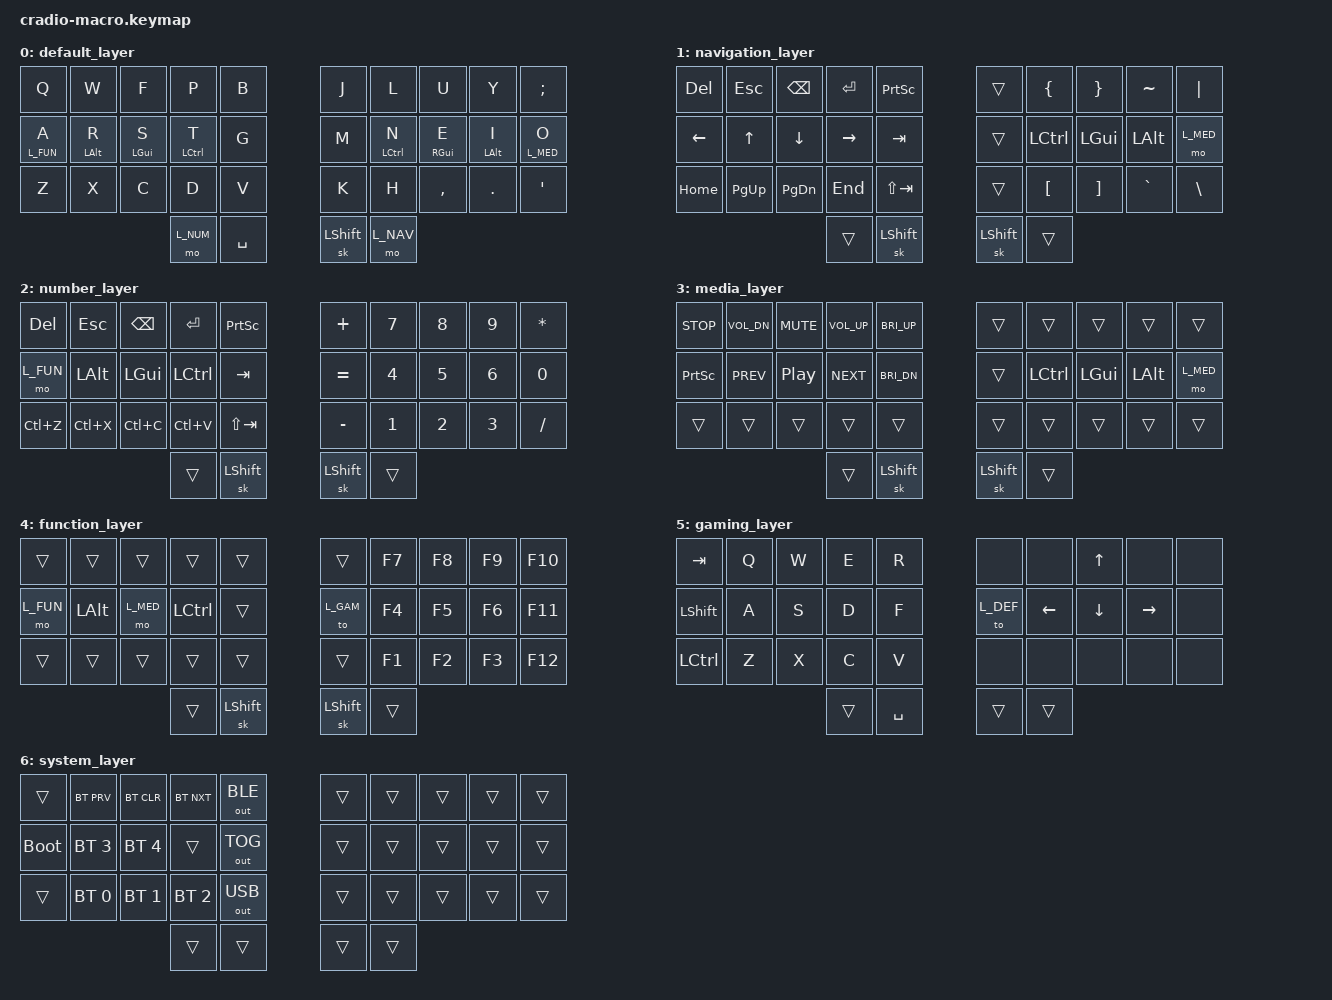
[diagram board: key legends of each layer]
/*
 * Copyright (c) 2020 The ZMK Contributors
 *
 * SPDX-License-Identifier: MIT
 */

#include <behaviors.dtsi>
#include <dt-bindings/zmk/bt.h>
#include <dt-bindings/zmk/keys.h>
#include <dt-bindings/zmk/outputs.h>

// GENERAL KEYS
#define GEN_NONE &none
#define GEN_TRAN &trans

#define GEN_CTRL &kp LCTRL
#define GEN_ALT &kp LALT
#define GEN_GUI &kp LGUI
#define GEN_FN &mo L_FUN
#define GEN_MED &mo L_MED

// DEFAULT LAYER

#define L_DEF 0

#define DEF_Q &kp Q
#define DEF_W &kp W
#define DEF_F &kp F
#define DEF_P &kp P
#define DEF_B &kp B
                        
#define DEF_A &lt L_FUN A 
#define DEF_R &mt LALT R 
#define DEF_S &mt LGUI S
#define DEF_T &mt LCTRL T 
#define DEF_G &kp G
        
#define DEF_Z &kp Z
#define DEF_X &kp X
#define DEF_C &kp C
#define DEF_D &kp D
#define DEF_V &kp V
                        

#define DEF_J &kp J
#define DEF_L &kp L
#define DEF_U &kp U
#define DEF_Y &kp Y
#define DEF_SEMI &kp SEMI

#define DEF_K &kp K
#define DEF_H &kp H
#define DEF_COMA &kp COMMA
#define DEF_DOT &kp DOT
#define DEF_QUOT &kp SQT

#define DEF_M &kp M
#define DEF_N &mt LCTRL N
#define DEF_E &mt RGUI E
#define DEF_I &mt LALT I 
#define DEF_O &lt L_MED O

#define DEF_SPC  &kp SPC
#define DEF_NAV  &mo L_NAV
#define DEF_NUM  &mo L_NUM
#define DEF_SHFT &sk LSHIFT

// NAVIGATION LAYER
#define L_NAV 1

#define NAV_CAPS &kp CAPS
#define NAV_BSLH &kp BSLH
#define NAV_PIPE &kp PIPE
#define NAV_HOME &kp HOME
#define NAV_UP &kp UP
#define NAV_END &kp END
#define NAV_PGUP &kp PG_UP

#define NAV_ESC &kp ESC
#define NAV_LEFT &kp LEFT
#define NAV_DOWN &kp DOWN
#define NAV_RGHT &kp RIGHT
#define NAV_TAB &kp TAB

#define NAV_GRV &kp GRAVE
#define NAV_TILD &kp TILDE
#define NAV_DEL &kp DEL
#define NAV_BSPC &kp BSPC
#define NAV_RET &kp RET
#define NAV_PGDN &kp PG_DN

// NUM LAYER
#define L_NUM 2

#define NUM_LBKT &kp LBKT
#define NUM_LBRC &kp LBRC
#define NUM_N7 &kp N7 
#define NUM_N8 &kp N8
#define NUM_N9 &kp N9
#define NUM_RBKT &kp RBKT 
#define NUM_RBRC &kp RBRC

#define NUM_EQUL &kp EQUAL
#define NUM_PLUS &kp PLUS
#define NUM_AST  &kp ASTERISK 

#define NUM_N4 &kp N4
#define NUM_N5 &kp N5
#define NUM_N6 &kp N6
#define NUM_N0 &kp N0

#define NUM_MIN &kp MINUS
#define NUM_N1 &kp N1
#define NUM_N2 &kp N2
#define NUM_N3 &kp N3
#define NUM_FSLH &kp FSLH

// MEDIA LAYER
#define L_MED 3

#define MED_BRID &kp C_BRI_DN
#define MED_VOLU &kp C_VOL_UP
#define MED_BRIU &kp C_BRI_UP


#define MED_PRNT &kp PSCRN
#define MED_PREV &kp C_PREV
#define MED_PLAY &kp C_PP
#define MED_NEXT &kp C_NEXT

#define MED_MUTE &kp C_MUTE
#define MED_VOLD &kp C_VOL_DN
#define MED_STOP &kp C_STOP

#define MED_UNDO &kp LC(Z)
#define MED_CUT  &kp LC(X)
#define MED_COPY &kp LC(C)
#define NUM_PST  &kp LC(V)
#define NUM_STAB &kp LS(TAB)

//FUNCTION LAYER
#define L_FUN 4

#define FUN_F7 &kp F7
#define FUN_F8 &kp F8
#define FUN_F9 &kp F9
#define FUN_F10 &kp F10

#define FUN_GAME &to L_GAM
#define FUN_F4 &kp F4
#define FUN_F5 &kp F5
#define FUN_F6 &kp F6
#define FUN_F11 &kp F11

#define FUN_BOOT &bootloader
#define FUN_F1 &kp F1
#define FUN_F2 &kp F2
#define FUN_F3 &kp F3
#define FUN_F13 &kp F12

#define FUN_SPC &kp LC(SPC)

// GAMING LAYER
#define L_GAM 5

#define GAM_TAB &kp TAB
#define GAM_Q &kp Q
#define GAM_W &kp W
#define GAM_E &kp E
#define GAM_R &kp R

#define GAM_LSFT &kp LSHIFT
#define GAM_A &kp A
#define GAM_S &kp S
#define GAM_D &kp D
#define GAM_F &kp F

#define GAM_LCTL &kp LCTRL
#define GAM_Z &kp Z
#define GAM_X &kp X
#define GAM_C &kp C
#define GAM_V &kp V


#define GAM_UP &kp UP

#define GAM_DEF &to L_DEF
#define GAM_LEFT &kp LEFT
#define GAM_DOWN &kp DOWN
#define GAM_RGHT &kp RIGHT

#define GAM_ESC &kp ESC
#define GAM_SPC &kp SPACE

// SYSTEM LAYER
#define L_SYS 6

#define SYS_BOOT &bootloader
#define SYS_BTCL &bt BT_CLR
#define SYS_BTNX &bt BT_NXT
#define SYS_BTPR &bt BT_PRV
#define SYS_BLE &out OUT_BLE
#define SYS_USB &out OUT_USB
#define SYS_OTG &out OUT_TOG
#define SYS_BT0 &bt BT_SEL 0
#define SYS_BT1 &bt BT_SEL 1
#define SYS_BT2 &bt BT_SEL 2
#define SYS_BT3 &bt BT_SEL 3
#define SYS_BT4 &bt BT_SEL 4

// POSITIONS
#define P_Q 0
#define P_W 1
#define P_F 2
#define P_P 3
#define P_B 4
#define P_J 5
#define P_L 6
#define P_U 7
#define P_Y 8
#define P_SEMI 9
#define P_A 10
#define P_R 11
#define P_S 12
#define P_T 13
#define P_G 14
#define P_M 15
#define P_N 16
#define P_E 17
#define P_I 18
#define P_O 19
#define P_Z 20
#define P_X 21
#define P_C 22
#define P_D 23
#define P_V 24
#define P_K 25
#define P_H 26
#define P_COMMA 27
#define P_DOT 28
#define P_SQT 29
#define P_COMBO 31 32

#define P_LALT 30
#define P_SPC 31
#define P_SHFT 32
#define P_RALT 33

#define COMBO_TIMEOUT 100
#define MACRO_TAP 10
#define MACRO_WAIT 0

&mt {
  flavor = "tap-preferred";
  tapping_term_ms = <200>;
};

&lt {
  flavor = "tap-preferred";
  tapping_term_ms = <200>;
};
&sl {
    release-after-ms = <1000>;
};
&sk {
    release-after-ms = <1000>;
    quick-release;
};
/ {
  macros {
    ZMK_MACRO(m_dot,
        wait-ms = <MACRO_WAIT>;
        tap-ms = <MACRO_TAP>;
        bindings = <&kp BSPC &kp DOT &kp SPACE>;
    )
    ZMK_MACRO(m_comma,
        wait-ms = <MACRO_WAIT>;
        tap-ms = <MACRO_TAP>;
        bindings = <&kp BSPC &kp COMMA &kp SPACE>;
    )
    ZMK_MACRO(m_ques,
        wait-ms = <MACRO_WAIT>;
        tap-ms = <MACRO_TAP>;
        bindings = <&kp BSPC &kp QUESTION &kp SPACE>;
    )
    // MACROS START
    ZMK_MACRO(spm_a,
        wait-ms = <MACRO_WAIT>;
        tap-ms = <MACRO_TAP>;
        bindings = <&kp A &kp SPACE>;
    )
    ZMK_MACRO(shm_a,
        wait-ms = <MACRO_WAIT>;
        tap-ms = <MACRO_TAP>;
        bindings = <&sk LSHIFT &kp A &kp SPACE>;
    )
    ZMK_MACRO(spm_I,
        wait-ms = <MACRO_WAIT>;
        tap-ms = <MACRO_TAP>;
        bindings = <&sk LSHIFT &kp I &kp SPACE>;
    )
    ZMK_MACRO(shm_I,
        wait-ms = <MACRO_WAIT>;
        tap-ms = <MACRO_TAP>;
        bindings = <&sk LSHIFT &sk LSHIFT &kp I &kp SPACE>;
    )
    ZMK_MACRO(spm_ISQTm,
        wait-ms = <MACRO_WAIT>;
        tap-ms = <MACRO_TAP>;
        bindings = <&sk LSHIFT &kp I &kp SQT &kp M &kp SPACE>;
    )
    ZMK_MACRO(shm_ISQTm,
        wait-ms = <MACRO_WAIT>;
        tap-ms = <MACRO_TAP>;
        bindings = <&sk LSHIFT &sk LSHIFT &kp I &kp SQT &kp M &kp SPACE>;
    )
    ZMK_MACRO(lm_ISQTm,
        wait-ms = <MACRO_WAIT>;
        tap-ms = <MACRO_TAP>;
        bindings = <&sk LSHIFT &kp I &kp SQT &kp V &kp E &kp SPACE>;
    )
    ZMK_MACRO(lsm_ISQTm,
        wait-ms = <MACRO_WAIT>;
        tap-ms = <MACRO_TAP>;
        bindings = <&sk LSHIFT &sk LSHIFT &kp I &kp SQT &kp V &kp E &kp SPACE>;
    )
    ZMK_MACRO(rm_ISQTm,
        wait-ms = <MACRO_WAIT>;
        tap-ms = <MACRO_TAP>;
        bindings = <&sk LSHIFT &kp I &kp SQT &kp L &kp L &kp SPACE>;
    )
    ZMK_MACRO(rsm_ISQTm,
        wait-ms = <MACRO_WAIT>;
        tap-ms = <MACRO_TAP>;
        bindings = <&sk LSHIFT &sk LSHIFT &kp I &kp SQT &kp L &kp L &kp SPACE>;
    )
    ZMK_MACRO(spm_ISQTve,
        wait-ms = <MACRO_WAIT>;
        tap-ms = <MACRO_TAP>;
        bindings = <&sk LSHIFT &kp I &kp SQT &kp V &kp E &kp SPACE>;
    )
    ZMK_MACRO(shm_ISQTve,
        wait-ms = <MACRO_WAIT>;
        tap-ms = <MACRO_TAP>;
        bindings = <&sk LSHIFT &sk LSHIFT &kp I &kp SQT &kp V &kp E &kp SPACE>;
    )
    ZMK_MACRO(spm_ISQTll,
        wait-ms = <MACRO_WAIT>;
        tap-ms = <MACRO_TAP>;
        bindings = <&sk LSHIFT &kp I &kp SQT &kp L &kp L &kp SPACE>;
    )
    ZMK_MACRO(shm_ISQTll,
        wait-ms = <MACRO_WAIT>;
        tap-ms = <MACRO_TAP>;
        bindings = <&sk LSHIFT &sk LSHIFT &kp I &kp SQT &kp L &kp L &kp SPACE>;
    )
    ZMK_MACRO(spm_an,
        wait-ms = <MACRO_WAIT>;
        tap-ms = <MACRO_TAP>;
        bindings = <&kp A &kp N &kp SPACE>;
    )
    ZMK_MACRO(shm_an,
        wait-ms = <MACRO_WAIT>;
        tap-ms = <MACRO_TAP>;
        bindings = <&sk LSHIFT &kp A &kp N &kp SPACE>;
    )
    ZMK_MACRO(spm_am,
        wait-ms = <MACRO_WAIT>;
        tap-ms = <MACRO_TAP>;
        bindings = <&kp A &kp M &kp SPACE>;
    )
    ZMK_MACRO(shm_am,
        wait-ms = <MACRO_WAIT>;
        tap-ms = <MACRO_TAP>;
        bindings = <&sk LSHIFT &kp A &kp M &kp SPACE>;
    )
    ZMK_MACRO(spm_as,
        wait-ms = <MACRO_WAIT>;
        tap-ms = <MACRO_TAP>;
        bindings = <&kp A &kp S &kp SPACE>;
    )
    ZMK_MACRO(shm_as,
        wait-ms = <MACRO_WAIT>;
        tap-ms = <MACRO_TAP>;
        bindings = <&sk LSHIFT &kp A &kp S &kp SPACE>;
    )
    ZMK_MACRO(spm_at,
        wait-ms = <MACRO_WAIT>;
        tap-ms = <MACRO_TAP>;
        bindings = <&kp A &kp T &kp SPACE>;
    )
    ZMK_MACRO(shm_at,
        wait-ms = <MACRO_WAIT>;
        tap-ms = <MACRO_TAP>;
        bindings = <&sk LSHIFT &kp A &kp T &kp SPACE>;
    )
    ZMK_MACRO(spm_be,
        wait-ms = <MACRO_WAIT>;
        tap-ms = <MACRO_TAP>;
        bindings = <&kp B &kp E &kp SPACE>;
    )
    ZMK_MACRO(shm_be,
        wait-ms = <MACRO_WAIT>;
        tap-ms = <MACRO_TAP>;
        bindings = <&sk LSHIFT &kp B &kp E &kp SPACE>;
    )
    ZMK_MACRO(spm_by,
        wait-ms = <MACRO_WAIT>;
        tap-ms = <MACRO_TAP>;
        bindings = <&kp B &kp Y &kp SPACE>;
    )
    ZMK_MACRO(shm_by,
        wait-ms = <MACRO_WAIT>;
        tap-ms = <MACRO_TAP>;
        bindings = <&sk LSHIFT &kp B &kp Y &kp SPACE>;
    )
    ZMK_MACRO(spm_do,
        wait-ms = <MACRO_WAIT>;
        tap-ms = <MACRO_TAP>;
        bindings = <&kp D &kp O &kp SPACE>;
    )
    ZMK_MACRO(shm_do,
        wait-ms = <MACRO_WAIT>;
        tap-ms = <MACRO_TAP>;
        bindings = <&sk LSHIFT &kp D &kp O &kp SPACE>;
    )
    ZMK_MACRO(lm_do,
        wait-ms = <MACRO_WAIT>;
        tap-ms = <MACRO_TAP>;
        bindings = <&kp D &kp I &kp D &kp SPACE>;
    )
    ZMK_MACRO(lsm_do,
        wait-ms = <MACRO_WAIT>;
        tap-ms = <MACRO_TAP>;
        bindings = <&sk LSHIFT &kp D &kp I &kp D &kp SPACE>;
    )
    ZMK_MACRO(rm_do,
        wait-ms = <MACRO_WAIT>;
        tap-ms = <MACRO_TAP>;
        bindings = <&kp D &kp O &kp I &kp N &kp G &kp SPACE>;
    )
    ZMK_MACRO(rsm_do,
        wait-ms = <MACRO_WAIT>;
        tap-ms = <MACRO_TAP>;
        bindings = <&sk LSHIFT &kp D &kp O &kp I &kp N &kp G &kp SPACE>;
    )
    ZMK_MACRO(spm_donSQTt,
        wait-ms = <MACRO_WAIT>;
        tap-ms = <MACRO_TAP>;
        bindings = <&kp D &kp O &kp N &kp SQT &kp T &kp SPACE>;
    )
    ZMK_MACRO(shm_donSQTt,
        wait-ms = <MACRO_WAIT>;
        tap-ms = <MACRO_TAP>;
        bindings = <&sk LSHIFT &kp D &kp O &kp N &kp SQT &kp T &kp SPACE>;
    )
    ZMK_MACRO(lm_donSQTt,
        wait-ms = <MACRO_WAIT>;
        tap-ms = <MACRO_TAP>;
        bindings = <&kp D &kp I &kp D &kp N &kp SQT &kp T &kp SPACE>;
    )
    ZMK_MACRO(lsm_donSQTt,
        wait-ms = <MACRO_WAIT>;
        tap-ms = <MACRO_TAP>;
        bindings = <&sk LSHIFT &kp D &kp I &kp D &kp N &kp SQT &kp T &kp SPACE>;
    )
    ZMK_MACRO(spm_go,
        wait-ms = <MACRO_WAIT>;
        tap-ms = <MACRO_TAP>;
        bindings = <&kp G &kp O &kp SPACE>;
    )
    ZMK_MACRO(shm_go,
        wait-ms = <MACRO_WAIT>;
        tap-ms = <MACRO_TAP>;
        bindings = <&sk LSHIFT &kp G &kp O &kp SPACE>;
    )
    ZMK_MACRO(spm_he,
        wait-ms = <MACRO_WAIT>;
        tap-ms = <MACRO_TAP>;
        bindings = <&kp H &kp E &kp SPACE>;
    )
    ZMK_MACRO(shm_he,
        wait-ms = <MACRO_WAIT>;
        tap-ms = <MACRO_TAP>;
        bindings = <&sk LSHIFT &kp H &kp E &kp SPACE>;
    )
    ZMK_MACRO(lm_he,
        wait-ms = <MACRO_WAIT>;
        tap-ms = <MACRO_TAP>;
        bindings = <&kp H &kp I &kp S &kp SPACE>;
    )
    ZMK_MACRO(lsm_he,
        wait-ms = <MACRO_WAIT>;
        tap-ms = <MACRO_TAP>;
        bindings = <&sk LSHIFT &kp H &kp I &kp S &kp SPACE>;
    )
    ZMK_MACRO(rm_he,
        wait-ms = <MACRO_WAIT>;
        tap-ms = <MACRO_TAP>;
        bindings = <&kp H &kp I &kp M &kp SPACE>;
    )
    ZMK_MACRO(rsm_he,
        wait-ms = <MACRO_WAIT>;
        tap-ms = <MACRO_TAP>;
        bindings = <&sk LSHIFT &kp H &kp I &kp M &kp SPACE>;
    )
    ZMK_MACRO(spm_hi,
        wait-ms = <MACRO_WAIT>;
        tap-ms = <MACRO_TAP>;
        bindings = <&kp H &kp I &kp SPACE>;
    )
    ZMK_MACRO(shm_hi,
        wait-ms = <MACRO_WAIT>;
        tap-ms = <MACRO_TAP>;
        bindings = <&sk LSHIFT &kp H &kp I &kp SPACE>;
    )
    ZMK_MACRO(lm_hi,
        wait-ms = <MACRO_WAIT>;
        tap-ms = <MACRO_TAP>;
        bindings = <&kp H &kp E &kp Y &kp SPACE>;
    )
    ZMK_MACRO(lsm_hi,
        wait-ms = <MACRO_WAIT>;
        tap-ms = <MACRO_TAP>;
        bindings = <&sk LSHIFT &kp H &kp E &kp Y &kp SPACE>;
    )
    ZMK_MACRO(rm_hi,
        wait-ms = <MACRO_WAIT>;
        tap-ms = <MACRO_TAP>;
        bindings = <&kp G &kp SQT &kp D &kp A &kp Y &kp SPACE>;
    )
    ZMK_MACRO(rsm_hi,
        wait-ms = <MACRO_WAIT>;
        tap-ms = <MACRO_TAP>;
        bindings = <&sk LSHIFT &kp G &kp SQT &kp D &kp A &kp Y &kp SPACE>;
    )
    ZMK_MACRO(spm_if,
        wait-ms = <MACRO_WAIT>;
        tap-ms = <MACRO_TAP>;
        bindings = <&kp I &kp F &kp SPACE>;
    )
    ZMK_MACRO(shm_if,
        wait-ms = <MACRO_WAIT>;
        tap-ms = <MACRO_TAP>;
        bindings = <&sk LSHIFT &kp I &kp F &kp SPACE>;
    )
    ZMK_MACRO(spm_in,
        wait-ms = <MACRO_WAIT>;
        tap-ms = <MACRO_TAP>;
        bindings = <&kp I &kp N &kp SPACE>;
    )
    ZMK_MACRO(shm_in,
        wait-ms = <MACRO_WAIT>;
        tap-ms = <MACRO_TAP>;
        bindings = <&sk LSHIFT &kp I &kp N &kp SPACE>;
    )
    ZMK_MACRO(spm_is,
        wait-ms = <MACRO_WAIT>;
        tap-ms = <MACRO_TAP>;
        bindings = <&kp I &kp S &kp SPACE>;
    )
    ZMK_MACRO(shm_is,
        wait-ms = <MACRO_WAIT>;
        tap-ms = <MACRO_TAP>;
        bindings = <&sk LSHIFT &kp I &kp S &kp SPACE>;
    )
    ZMK_MACRO(lm_is,
        wait-ms = <MACRO_WAIT>;
        tap-ms = <MACRO_TAP>;
        bindings = <&kp I &kp S &kp N &kp SQT &kp T &kp SPACE>;
    )
    ZMK_MACRO(lsm_is,
        wait-ms = <MACRO_WAIT>;
        tap-ms = <MACRO_TAP>;
        bindings = <&sk LSHIFT &kp I &kp S &kp N &kp SQT &kp T &kp SPACE>;
    )
    ZMK_MACRO(spm_it,
        wait-ms = <MACRO_WAIT>;
        tap-ms = <MACRO_TAP>;
        bindings = <&kp I &kp T &kp SPACE>;
    )
    ZMK_MACRO(shm_it,
        wait-ms = <MACRO_WAIT>;
        tap-ms = <MACRO_TAP>;
        bindings = <&sk LSHIFT &kp I &kp T &kp SPACE>;
    )
    ZMK_MACRO(lm_it,
        wait-ms = <MACRO_WAIT>;
        tap-ms = <MACRO_TAP>;
        bindings = <&kp I &kp T &kp S &kp SPACE>;
    )
    ZMK_MACRO(lsm_it,
        wait-ms = <MACRO_WAIT>;
        tap-ms = <MACRO_TAP>;
        bindings = <&sk LSHIFT &kp I &kp T &kp S &kp SPACE>;
    )
    ZMK_MACRO(rm_it,
        wait-ms = <MACRO_WAIT>;
        tap-ms = <MACRO_TAP>;
        bindings = <&kp I &kp T &kp SQT &kp S &kp SPACE>;
    )
    ZMK_MACRO(rsm_it,
        wait-ms = <MACRO_WAIT>;
        tap-ms = <MACRO_TAP>;
        bindings = <&sk LSHIFT &kp I &kp T &kp SQT &kp S &kp SPACE>;
    )
    ZMK_MACRO(spm_me,
        wait-ms = <MACRO_WAIT>;
        tap-ms = <MACRO_TAP>;
        bindings = <&kp M &kp E &kp SPACE>;
    )
    ZMK_MACRO(shm_me,
        wait-ms = <MACRO_WAIT>;
        tap-ms = <MACRO_TAP>;
        bindings = <&sk LSHIFT &kp M &kp E &kp SPACE>;
    )
    ZMK_MACRO(lm_me,
        wait-ms = <MACRO_WAIT>;
        tap-ms = <MACRO_TAP>;
        bindings = <&kp M &kp Y &kp SPACE>;
    )
    ZMK_MACRO(lsm_me,
        wait-ms = <MACRO_WAIT>;
        tap-ms = <MACRO_TAP>;
        bindings = <&sk LSHIFT &kp M &kp Y &kp SPACE>;
    )
    ZMK_MACRO(rm_me,
        wait-ms = <MACRO_WAIT>;
        tap-ms = <MACRO_TAP>;
        bindings = <&kp M &kp I &kp N &kp E &kp SPACE>;
    )
    ZMK_MACRO(rsm_me,
        wait-ms = <MACRO_WAIT>;
        tap-ms = <MACRO_TAP>;
        bindings = <&sk LSHIFT &kp M &kp I &kp N &kp E &kp SPACE>;
    )
    ZMK_MACRO(spm_no,
        wait-ms = <MACRO_WAIT>;
        tap-ms = <MACRO_TAP>;
        bindings = <&kp N &kp O &kp SPACE>;
    )
    ZMK_MACRO(shm_no,
        wait-ms = <MACRO_WAIT>;
        tap-ms = <MACRO_TAP>;
        bindings = <&sk LSHIFT &kp N &kp O &kp SPACE>;
    )
    ZMK_MACRO(spm_of,
        wait-ms = <MACRO_WAIT>;
        tap-ms = <MACRO_TAP>;
        bindings = <&kp O &kp F &kp SPACE>;
    )
    ZMK_MACRO(shm_of,
        wait-ms = <MACRO_WAIT>;
        tap-ms = <MACRO_TAP>;
        bindings = <&sk LSHIFT &kp O &kp F &kp SPACE>;
    )
    ZMK_MACRO(spm_on,
        wait-ms = <MACRO_WAIT>;
        tap-ms = <MACRO_TAP>;
        bindings = <&kp O &kp N &kp SPACE>;
    )
    ZMK_MACRO(shm_on,
        wait-ms = <MACRO_WAIT>;
        tap-ms = <MACRO_TAP>;
        bindings = <&sk LSHIFT &kp O &kp N &kp SPACE>;
    )
    ZMK_MACRO(spm_or,
        wait-ms = <MACRO_WAIT>;
        tap-ms = <MACRO_TAP>;
        bindings = <&kp O &kp R &kp SPACE>;
    )
    ZMK_MACRO(shm_or,
        wait-ms = <MACRO_WAIT>;
        tap-ms = <MACRO_TAP>;
        bindings = <&sk LSHIFT &kp O &kp R &kp SPACE>;
    )
    ZMK_MACRO(spm_so,
        wait-ms = <MACRO_WAIT>;
        tap-ms = <MACRO_TAP>;
        bindings = <&kp S &kp O &kp SPACE>;
    )
    ZMK_MACRO(shm_so,
        wait-ms = <MACRO_WAIT>;
        tap-ms = <MACRO_TAP>;
        bindings = <&sk LSHIFT &kp S &kp O &kp SPACE>;
    )
    ZMK_MACRO(spm_to,
        wait-ms = <MACRO_WAIT>;
        tap-ms = <MACRO_TAP>;
        bindings = <&kp T &kp O &kp SPACE>;
    )
    ZMK_MACRO(shm_to,
        wait-ms = <MACRO_WAIT>;
        tap-ms = <MACRO_TAP>;
        bindings = <&sk LSHIFT &kp T &kp O &kp SPACE>;
    )
    ZMK_MACRO(spm_up,
        wait-ms = <MACRO_WAIT>;
        tap-ms = <MACRO_TAP>;
        bindings = <&kp U &kp P &kp SPACE>;
    )
    ZMK_MACRO(shm_up,
        wait-ms = <MACRO_WAIT>;
        tap-ms = <MACRO_TAP>;
        bindings = <&sk LSHIFT &kp U &kp P &kp SPACE>;
    )
    ZMK_MACRO(spm_us,
        wait-ms = <MACRO_WAIT>;
        tap-ms = <MACRO_TAP>;
        bindings = <&kp U &kp S &kp SPACE>;
    )
    ZMK_MACRO(shm_us,
        wait-ms = <MACRO_WAIT>;
        tap-ms = <MACRO_TAP>;
        bindings = <&sk LSHIFT &kp U &kp S &kp SPACE>;
    )
    ZMK_MACRO(spm_we,
        wait-ms = <MACRO_WAIT>;
        tap-ms = <MACRO_TAP>;
        bindings = <&kp W &kp E &kp SPACE>;
    )
    ZMK_MACRO(shm_we,
        wait-ms = <MACRO_WAIT>;
        tap-ms = <MACRO_TAP>;
        bindings = <&sk LSHIFT &kp W &kp E &kp SPACE>;
    )
    ZMK_MACRO(spm_weSQTre,
        wait-ms = <MACRO_WAIT>;
        tap-ms = <MACRO_TAP>;
        bindings = <&kp W &kp E &kp SQT &kp R &kp E &kp SPACE>;
    )
    ZMK_MACRO(shm_weSQTre,
        wait-ms = <MACRO_WAIT>;
        tap-ms = <MACRO_TAP>;
        bindings = <&sk LSHIFT &kp W &kp E &kp SQT &kp R &kp E &kp SPACE>;
    )
    ZMK_MACRO(lm_weSQTre,
        wait-ms = <MACRO_WAIT>;
        tap-ms = <MACRO_TAP>;
        bindings = <&kp W &kp E &kp SQT &kp V &kp E &kp SPACE>;
    )
    ZMK_MACRO(lsm_weSQTre,
        wait-ms = <MACRO_WAIT>;
        tap-ms = <MACRO_TAP>;
        bindings = <&sk LSHIFT &kp W &kp E &kp SQT &kp V &kp E &kp SPACE>;
    )
    ZMK_MACRO(rm_weSQTre,
        wait-ms = <MACRO_WAIT>;
        tap-ms = <MACRO_TAP>;
        bindings = <&kp W &kp E &kp SQT &kp L &kp L &kp SPACE>;
    )
    ZMK_MACRO(rsm_weSQTre,
        wait-ms = <MACRO_WAIT>;
        tap-ms = <MACRO_TAP>;
        bindings = <&sk LSHIFT &kp W &kp E &kp SQT &kp L &kp L &kp SPACE>;
    )
    ZMK_MACRO(spm_weSQTve,
        wait-ms = <MACRO_WAIT>;
        tap-ms = <MACRO_TAP>;
        bindings = <&kp W &kp E &kp SQT &kp V &kp E &kp SPACE>;
    )
    ZMK_MACRO(shm_weSQTve,
        wait-ms = <MACRO_WAIT>;
        tap-ms = <MACRO_TAP>;
        bindings = <&sk LSHIFT &kp W &kp E &kp SQT &kp V &kp E &kp SPACE>;
    )
    ZMK_MACRO(spm_weSQTll,
        wait-ms = <MACRO_WAIT>;
        tap-ms = <MACRO_TAP>;
        bindings = <&kp W &kp E &kp SQT &kp L &kp L &kp SPACE>;
    )
    ZMK_MACRO(shm_weSQTll,
        wait-ms = <MACRO_WAIT>;
        tap-ms = <MACRO_TAP>;
        bindings = <&sk LSHIFT &kp W &kp E &kp SQT &kp L &kp L &kp SPACE>;
    )
    ZMK_MACRO(spm_OK,
        wait-ms = <MACRO_WAIT>;
        tap-ms = <MACRO_TAP>;
        bindings = <&sk LSHIFT &kp O &sk LSHIFT &kp K &kp SPACE>;
    )
    ZMK_MACRO(shm_OK,
        wait-ms = <MACRO_WAIT>;
        tap-ms = <MACRO_TAP>;
        bindings = <&sk LSHIFT &sk LSHIFT &kp O &sk LSHIFT &kp K &kp SPACE>;
    )
    ZMK_MACRO(spm_all,
        wait-ms = <MACRO_WAIT>;
        tap-ms = <MACRO_TAP>;
        bindings = <&kp A &kp L &kp L &kp SPACE>;
    )
    ZMK_MACRO(shm_all,
        wait-ms = <MACRO_WAIT>;
        tap-ms = <MACRO_TAP>;
        bindings = <&sk LSHIFT &kp A &kp L &kp L &kp SPACE>;
    )
    ZMK_MACRO(spm_and,
        wait-ms = <MACRO_WAIT>;
        tap-ms = <MACRO_TAP>;
        bindings = <&kp A &kp N &kp D &kp SPACE>;
    )
    ZMK_MACRO(shm_and,
        wait-ms = <MACRO_WAIT>;
        tap-ms = <MACRO_TAP>;
        bindings = <&sk LSHIFT &kp A &kp N &kp D &kp SPACE>;
    )
    ZMK_MACRO(spm_any,
        wait-ms = <MACRO_WAIT>;
        tap-ms = <MACRO_TAP>;
        bindings = <&kp A &kp N &kp Y &kp SPACE>;
    )
    ZMK_MACRO(shm_any,
        wait-ms = <MACRO_WAIT>;
        tap-ms = <MACRO_TAP>;
        bindings = <&sk LSHIFT &kp A &kp N &kp Y &kp SPACE>;
    )
    ZMK_MACRO(spm_but,
        wait-ms = <MACRO_WAIT>;
        tap-ms = <MACRO_TAP>;
        bindings = <&kp B &kp U &kp T &kp SPACE>;
    )
    ZMK_MACRO(shm_but,
        wait-ms = <MACRO_WAIT>;
        tap-ms = <MACRO_TAP>;
        bindings = <&sk LSHIFT &kp B &kp U &kp T &kp SPACE>;
    )
    ZMK_MACRO(spm_can,
        wait-ms = <MACRO_WAIT>;
        tap-ms = <MACRO_TAP>;
        bindings = <&kp C &kp A &kp N &kp SPACE>;
    )
    ZMK_MACRO(shm_can,
        wait-ms = <MACRO_WAIT>;
        tap-ms = <MACRO_TAP>;
        bindings = <&sk LSHIFT &kp C &kp A &kp N &kp SPACE>;
    )
    ZMK_MACRO(lm_can,
        wait-ms = <MACRO_WAIT>;
        tap-ms = <MACRO_TAP>;
        bindings = <&kp C &kp A &kp N &kp SQT &kp T &kp SPACE>;
    )
    ZMK_MACRO(lsm_can,
        wait-ms = <MACRO_WAIT>;
        tap-ms = <MACRO_TAP>;
        bindings = <&sk LSHIFT &kp C &kp A &kp N &kp SQT &kp T &kp SPACE>;
    )
    ZMK_MACRO(spm_could,
        wait-ms = <MACRO_WAIT>;
        tap-ms = <MACRO_TAP>;
        bindings = <&kp C &kp O &kp U &kp L &kp D &kp SPACE>;
    )
    ZMK_MACRO(shm_could,
        wait-ms = <MACRO_WAIT>;
        tap-ms = <MACRO_TAP>;
        bindings = <&sk LSHIFT &kp C &kp O &kp U &kp L &kp D &kp SPACE>;
    )
    ZMK_MACRO(lm_could,
        wait-ms = <MACRO_WAIT>;
        tap-ms = <MACRO_TAP>;
        bindings = <&kp C &kp O &kp U &kp L &kp D &kp N &kp SQT &kp T &kp SPACE>;
    )
    ZMK_MACRO(lsm_could,
        wait-ms = <MACRO_WAIT>;
        tap-ms = <MACRO_TAP>;
        bindings = <&sk LSHIFT &kp C &kp O &kp U &kp L &kp D &kp N &kp SQT &kp T &kp SPACE>;
    )
    ZMK_MACRO(spm_day,
        wait-ms = <MACRO_WAIT>;
        tap-ms = <MACRO_TAP>;
        bindings = <&kp D &kp A &kp Y &kp SPACE>;
    )
    ZMK_MACRO(shm_day,
        wait-ms = <MACRO_WAIT>;
        tap-ms = <MACRO_TAP>;
        bindings = <&sk LSHIFT &kp D &kp A &kp Y &kp SPACE>;
    )
    ZMK_MACRO(lm_day,
        wait-ms = <MACRO_WAIT>;
        tap-ms = <MACRO_TAP>;
        bindings = <&kp D &kp A &kp Y &kp S &kp SPACE>;
    )
    ZMK_MACRO(lsm_day,
        wait-ms = <MACRO_WAIT>;
        tap-ms = <MACRO_TAP>;
        bindings = <&sk LSHIFT &kp D &kp A &kp Y &kp S &kp SPACE>;
    )
    ZMK_MACRO(spm_for,
        wait-ms = <MACRO_WAIT>;
        tap-ms = <MACRO_TAP>;
        bindings = <&kp F &kp O &kp R &kp SPACE>;
    )
    ZMK_MACRO(shm_for,
        wait-ms = <MACRO_WAIT>;
        tap-ms = <MACRO_TAP>;
        bindings = <&sk LSHIFT &kp F &kp O &kp R &kp SPACE>;
    )
    ZMK_MACRO(spm_get,
        wait-ms = <MACRO_WAIT>;
        tap-ms = <MACRO_TAP>;
        bindings = <&kp G &kp E &kp T &kp SPACE>;
    )
    ZMK_MACRO(shm_get,
        wait-ms = <MACRO_WAIT>;
        tap-ms = <MACRO_TAP>;
        bindings = <&sk LSHIFT &kp G &kp E &kp T &kp SPACE>;
    )
    ZMK_MACRO(lm_get,
        wait-ms = <MACRO_WAIT>;
        tap-ms = <MACRO_TAP>;
        bindings = <&kp G &kp O &kp T &kp SPACE>;
    )
    ZMK_MACRO(lsm_get,
        wait-ms = <MACRO_WAIT>;
        tap-ms = <MACRO_TAP>;
        bindings = <&sk LSHIFT &kp G &kp O &kp T &kp SPACE>;
    )
    ZMK_MACRO(rm_get,
        wait-ms = <MACRO_WAIT>;
        tap-ms = <MACRO_TAP>;
        bindings = <&kp G &kp E &kp T &kp T &kp I &kp N &kp G &kp SPACE>;
    )
    ZMK_MACRO(rsm_get,
        wait-ms = <MACRO_WAIT>;
        tap-ms = <MACRO_TAP>;
        bindings = <&sk LSHIFT &kp G &kp E &kp T &kp T &kp I &kp N &kp G &kp SPACE>;
    )
    ZMK_MACRO(spm_how,
        wait-ms = <MACRO_WAIT>;
        tap-ms = <MACRO_TAP>;
        bindings = <&kp H &kp O &kp W &kp SPACE>;
    )
    ZMK_MACRO(shm_how,
        wait-ms = <MACRO_WAIT>;
        tap-ms = <MACRO_TAP>;
        bindings = <&sk LSHIFT &kp H &kp O &kp W &kp SPACE>;
    )
    ZMK_MACRO(spm_new,
        wait-ms = <MACRO_WAIT>;
        tap-ms = <MACRO_TAP>;
        bindings = <&kp N &kp E &kp W &kp SPACE>;
    )
    ZMK_MACRO(shm_new,
        wait-ms = <MACRO_WAIT>;
        tap-ms = <MACRO_TAP>;
        bindings = <&sk LSHIFT &kp N &kp E &kp W &kp SPACE>;
    )
    ZMK_MACRO(spm_not,
        wait-ms = <MACRO_WAIT>;
        tap-ms = <MACRO_TAP>;
        bindings = <&kp N &kp O &kp T &kp SPACE>;
    )
    ZMK_MACRO(shm_not,
        wait-ms = <MACRO_WAIT>;
        tap-ms = <MACRO_TAP>;
        bindings = <&sk LSHIFT &kp N &kp O &kp T &kp SPACE>;
    )
    ZMK_MACRO(spm_now,
        wait-ms = <MACRO_WAIT>;
        tap-ms = <MACRO_TAP>;
        bindings = <&kp N &kp O &kp W &kp SPACE>;
    )
    ZMK_MACRO(shm_now,
        wait-ms = <MACRO_WAIT>;
        tap-ms = <MACRO_TAP>;
        bindings = <&sk LSHIFT &kp N &kp O &kp W &kp SPACE>;
    )
    ZMK_MACRO(spm_one,
        wait-ms = <MACRO_WAIT>;
        tap-ms = <MACRO_TAP>;
        bindings = <&kp O &kp N &kp E &kp SPACE>;
    )
    ZMK_MACRO(shm_one,
        wait-ms = <MACRO_WAIT>;
        tap-ms = <MACRO_TAP>;
        bindings = <&sk LSHIFT &kp O &kp N &kp E &kp SPACE>;
    )
    ZMK_MACRO(spm_our,
        wait-ms = <MACRO_WAIT>;
        tap-ms = <MACRO_TAP>;
        bindings = <&kp O &kp U &kp R &kp SPACE>;
    )
    ZMK_MACRO(shm_our,
        wait-ms = <MACRO_WAIT>;
        tap-ms = <MACRO_TAP>;
        bindings = <&sk LSHIFT &kp O &kp U &kp R &kp SPACE>;
    )
    ZMK_MACRO(lm_our,
        wait-ms = <MACRO_WAIT>;
        tap-ms = <MACRO_TAP>;
        bindings = <&kp O &kp U &kp R &kp S &kp SPACE>;
    )
    ZMK_MACRO(lsm_our,
        wait-ms = <MACRO_WAIT>;
        tap-ms = <MACRO_TAP>;
        bindings = <&sk LSHIFT &kp O &kp U &kp R &kp S &kp SPACE>;
    )
    ZMK_MACRO(spm_out,
        wait-ms = <MACRO_WAIT>;
        tap-ms = <MACRO_TAP>;
        bindings = <&kp O &kp U &kp T &kp SPACE>;
    )
    ZMK_MACRO(shm_out,
        wait-ms = <MACRO_WAIT>;
        tap-ms = <MACRO_TAP>;
        bindings = <&sk LSHIFT &kp O &kp U &kp T &kp SPACE>;
    )
    ZMK_MACRO(spm_say,
        wait-ms = <MACRO_WAIT>;
        tap-ms = <MACRO_TAP>;
        bindings = <&kp S &kp A &kp Y &kp SPACE>;
    )
    ZMK_MACRO(shm_say,
        wait-ms = <MACRO_WAIT>;
        tap-ms = <MACRO_TAP>;
        bindings = <&sk LSHIFT &kp S &kp A &kp Y &kp SPACE>;
    )
    ZMK_MACRO(lm_say,
        wait-ms = <MACRO_WAIT>;
        tap-ms = <MACRO_TAP>;
        bindings = <&kp S &kp A &kp I &kp D &kp SPACE>;
    )
    ZMK_MACRO(lsm_say,
        wait-ms = <MACRO_WAIT>;
        tap-ms = <MACRO_TAP>;
        bindings = <&sk LSHIFT &kp S &kp A &kp I &kp D &kp SPACE>;
    )
    ZMK_MACRO(rm_say,
        wait-ms = <MACRO_WAIT>;
        tap-ms = <MACRO_TAP>;
        bindings = <&kp S &kp A &kp Y &kp I &kp N &kp G &kp SPACE>;
    )
    ZMK_MACRO(rsm_say,
        wait-ms = <MACRO_WAIT>;
        tap-ms = <MACRO_TAP>;
        bindings = <&sk LSHIFT &kp S &kp A &kp Y &kp I &kp N &kp G &kp SPACE>;
    )
    ZMK_MACRO(spm_see,
        wait-ms = <MACRO_WAIT>;
        tap-ms = <MACRO_TAP>;
        bindings = <&kp S &kp E &kp E &kp SPACE>;
    )
    ZMK_MACRO(shm_see,
        wait-ms = <MACRO_WAIT>;
        tap-ms = <MACRO_TAP>;
        bindings = <&sk LSHIFT &kp S &kp E &kp E &kp SPACE>;
    )
    ZMK_MACRO(lm_see,
        wait-ms = <MACRO_WAIT>;
        tap-ms = <MACRO_TAP>;
        bindings = <&kp S &kp A &kp W &kp SPACE>;
    )
    ZMK_MACRO(lsm_see,
        wait-ms = <MACRO_WAIT>;
        tap-ms = <MACRO_TAP>;
        bindings = <&sk LSHIFT &kp S &kp A &kp W &kp SPACE>;
    )
    ZMK_MACRO(rm_see,
        wait-ms = <MACRO_WAIT>;
        tap-ms = <MACRO_TAP>;
        bindings = <&kp S &kp E &kp E &kp I &kp N &kp G &kp SPACE>;
    )
    ZMK_MACRO(rsm_see,
        wait-ms = <MACRO_WAIT>;
        tap-ms = <MACRO_TAP>;
        bindings = <&sk LSHIFT &kp S &kp E &kp E &kp I &kp N &kp G &kp SPACE>;
    )
    ZMK_MACRO(spm_she,
        wait-ms = <MACRO_WAIT>;
        tap-ms = <MACRO_TAP>;
        bindings = <&kp S &kp H &kp E &kp SPACE>;
    )
    ZMK_MACRO(shm_she,
        wait-ms = <MACRO_WAIT>;
        tap-ms = <MACRO_TAP>;
        bindings = <&sk LSHIFT &kp S &kp H &kp E &kp SPACE>;
    )
    ZMK_MACRO(lm_she,
        wait-ms = <MACRO_WAIT>;
        tap-ms = <MACRO_TAP>;
        bindings = <&kp H &kp E &kp R &kp SPACE>;
    )
    ZMK_MACRO(lsm_she,
        wait-ms = <MACRO_WAIT>;
        tap-ms = <MACRO_TAP>;
        bindings = <&sk LSHIFT &kp H &kp E &kp R &kp SPACE>;
    )
    ZMK_MACRO(rm_she,
        wait-ms = <MACRO_WAIT>;
        tap-ms = <MACRO_TAP>;
        bindings = <&kp H &kp E &kp R &kp S &kp SPACE>;
    )
    ZMK_MACRO(rsm_she,
        wait-ms = <MACRO_WAIT>;
        tap-ms = <MACRO_TAP>;
        bindings = <&sk LSHIFT &kp H &kp E &kp R &kp S &kp SPACE>;
    )
    ZMK_MACRO(spm_the,
        wait-ms = <MACRO_WAIT>;
        tap-ms = <MACRO_TAP>;
        bindings = <&kp T &kp H &kp E &kp SPACE>;
    )
    ZMK_MACRO(shm_the,
        wait-ms = <MACRO_WAIT>;
        tap-ms = <MACRO_TAP>;
        bindings = <&sk LSHIFT &kp T &kp H &kp E &kp SPACE>;
    )
    ZMK_MACRO(spm_two,
        wait-ms = <MACRO_WAIT>;
        tap-ms = <MACRO_TAP>;
        bindings = <&kp T &kp W &kp O &kp SPACE>;
    )
    ZMK_MACRO(shm_two,
        wait-ms = <MACRO_WAIT>;
        tap-ms = <MACRO_TAP>;
        bindings = <&sk LSHIFT &kp T &kp W &kp O &kp SPACE>;
    )
    ZMK_MACRO(spm_use,
        wait-ms = <MACRO_WAIT>;
        tap-ms = <MACRO_TAP>;
        bindings = <&kp U &kp S &kp E &kp SPACE>;
    )
    ZMK_MACRO(shm_use,
        wait-ms = <MACRO_WAIT>;
        tap-ms = <MACRO_TAP>;
        bindings = <&sk LSHIFT &kp U &kp S &kp E &kp SPACE>;
    )
    ZMK_MACRO(lm_use,
        wait-ms = <MACRO_WAIT>;
        tap-ms = <MACRO_TAP>;
        bindings = <&kp U &kp S &kp E &kp D &kp SPACE>;
    )
    ZMK_MACRO(lsm_use,
        wait-ms = <MACRO_WAIT>;
        tap-ms = <MACRO_TAP>;
        bindings = <&sk LSHIFT &kp U &kp S &kp E &kp D &kp SPACE>;
    )
    ZMK_MACRO(rm_use,
        wait-ms = <MACRO_WAIT>;
        tap-ms = <MACRO_TAP>;
        bindings = <&kp U &kp S &kp I &kp N &kp G &kp SPACE>;
    )
    ZMK_MACRO(rsm_use,
        wait-ms = <MACRO_WAIT>;
        tap-ms = <MACRO_TAP>;
        bindings = <&sk LSHIFT &kp U &kp S &kp I &kp N &kp G &kp SPACE>;
    )
    ZMK_MACRO(spm_was,
        wait-ms = <MACRO_WAIT>;
        tap-ms = <MACRO_TAP>;
        bindings = <&kp W &kp A &kp S &kp SPACE>;
    )
    ZMK_MACRO(shm_was,
        wait-ms = <MACRO_WAIT>;
        tap-ms = <MACRO_TAP>;
        bindings = <&sk LSHIFT &kp W &kp A &kp S &kp SPACE>;
    )
    ZMK_MACRO(spm_way,
        wait-ms = <MACRO_WAIT>;
        tap-ms = <MACRO_TAP>;
        bindings = <&kp W &kp A &kp Y &kp SPACE>;
    )
    ZMK_MACRO(shm_way,
        wait-ms = <MACRO_WAIT>;
        tap-ms = <MACRO_TAP>;
        bindings = <&sk LSHIFT &kp W &kp A &kp Y &kp SPACE>;
    )
    ZMK_MACRO(spm_who,
        wait-ms = <MACRO_WAIT>;
        tap-ms = <MACRO_TAP>;
        bindings = <&kp W &kp H &kp O &kp SPACE>;
    )
    ZMK_MACRO(shm_who,
        wait-ms = <MACRO_WAIT>;
        tap-ms = <MACRO_TAP>;
        bindings = <&sk LSHIFT &kp W &kp H &kp O &kp SPACE>;
    )
    ZMK_MACRO(spm_you,
        wait-ms = <MACRO_WAIT>;
        tap-ms = <MACRO_TAP>;
        bindings = <&kp Y &kp O &kp U &kp SPACE>;
    )
    ZMK_MACRO(shm_you,
        wait-ms = <MACRO_WAIT>;
        tap-ms = <MACRO_TAP>;
        bindings = <&sk LSHIFT &kp Y &kp O &kp U &kp SPACE>;
    )
    ZMK_MACRO(lm_you,
        wait-ms = <MACRO_WAIT>;
        tap-ms = <MACRO_TAP>;
        bindings = <&kp Y &kp O &kp U &kp R &kp SPACE>;
    )
    ZMK_MACRO(lsm_you,
        wait-ms = <MACRO_WAIT>;
        tap-ms = <MACRO_TAP>;
        bindings = <&sk LSHIFT &kp Y &kp O &kp U &kp R &kp SPACE>;
    )
    ZMK_MACRO(rm_you,
        wait-ms = <MACRO_WAIT>;
        tap-ms = <MACRO_TAP>;
        bindings = <&kp Y &kp O &kp U &kp R &kp S &kp SPACE>;
    )
    ZMK_MACRO(rsm_you,
        wait-ms = <MACRO_WAIT>;
        tap-ms = <MACRO_TAP>;
        bindings = <&sk LSHIFT &kp Y &kp O &kp U &kp R &kp S &kp SPACE>;
    )
    ZMK_MACRO(spm_youSQTre,
        wait-ms = <MACRO_WAIT>;
        tap-ms = <MACRO_TAP>;
        bindings = <&kp Y &kp O &kp U &kp SQT &kp R &kp E &kp SPACE>;
    )
    ZMK_MACRO(shm_youSQTre,
        wait-ms = <MACRO_WAIT>;
        tap-ms = <MACRO_TAP>;
        bindings = <&sk LSHIFT &kp Y &kp O &kp U &kp SQT &kp R &kp E &kp SPACE>;
    )
    ZMK_MACRO(lm_youSQTre,
        wait-ms = <MACRO_WAIT>;
        tap-ms = <MACRO_TAP>;
        bindings = <&kp Y &kp O &kp U &kp SQT &kp V &kp E &kp SPACE>;
    )
    ZMK_MACRO(lsm_youSQTre,
        wait-ms = <MACRO_WAIT>;
        tap-ms = <MACRO_TAP>;
        bindings = <&sk LSHIFT &kp Y &kp O &kp U &kp SQT &kp V &kp E &kp SPACE>;
    )
    ZMK_MACRO(rm_youSQTre,
        wait-ms = <MACRO_WAIT>;
        tap-ms = <MACRO_TAP>;
        bindings = <&kp Y &kp O &kp U &kp SQT &kp L &kp L &kp SPACE>;
    )
    ZMK_MACRO(rsm_youSQTre,
        wait-ms = <MACRO_WAIT>;
        tap-ms = <MACRO_TAP>;
        bindings = <&sk LSHIFT &kp Y &kp O &kp U &kp SQT &kp L &kp L &kp SPACE>;
    )
    ZMK_MACRO(spm_youSQTve,
        wait-ms = <MACRO_WAIT>;
        tap-ms = <MACRO_TAP>;
        bindings = <&kp Y &kp O &kp U &kp SQT &kp V &kp E &kp SPACE>;
    )
    ZMK_MACRO(shm_youSQTve,
        wait-ms = <MACRO_WAIT>;
        tap-ms = <MACRO_TAP>;
        bindings = <&sk LSHIFT &kp Y &kp O &kp U &kp SQT &kp V &kp E &kp SPACE>;
    )
    ZMK_MACRO(spm_youSQTll,
        wait-ms = <MACRO_WAIT>;
        tap-ms = <MACRO_TAP>;
        bindings = <&kp Y &kp O &kp U &kp SQT &kp L &kp L &kp SPACE>;
    )
    ZMK_MACRO(shm_youSQTll,
        wait-ms = <MACRO_WAIT>;
        tap-ms = <MACRO_TAP>;
        bindings = <&sk LSHIFT &kp Y &kp O &kp U &kp SQT &kp L &kp L &kp SPACE>;
    )
    ZMK_MACRO(spm_also,
        wait-ms = <MACRO_WAIT>;
        tap-ms = <MACRO_TAP>;
        bindings = <&kp A &kp L &kp S &kp O &kp SPACE>;
    )
    ZMK_MACRO(shm_also,
        wait-ms = <MACRO_WAIT>;
        tap-ms = <MACRO_TAP>;
        bindings = <&sk LSHIFT &kp A &kp L &kp S &kp O &kp SPACE>;
    )
    ZMK_MACRO(spm_back,
        wait-ms = <MACRO_WAIT>;
        tap-ms = <MACRO_TAP>;
        bindings = <&kp B &kp A &kp C &kp K &kp SPACE>;
    )
    ZMK_MACRO(shm_back,
        wait-ms = <MACRO_WAIT>;
        tap-ms = <MACRO_TAP>;
        bindings = <&sk LSHIFT &kp B &kp A &kp C &kp K &kp SPACE>;
    )
    ZMK_MACRO(spm_come,
        wait-ms = <MACRO_WAIT>;
        tap-ms = <MACRO_TAP>;
        bindings = <&kp C &kp O &kp M &kp E &kp SPACE>;
    )
    ZMK_MACRO(shm_come,
        wait-ms = <MACRO_WAIT>;
        tap-ms = <MACRO_TAP>;
        bindings = <&sk LSHIFT &kp C &kp O &kp M &kp E &kp SPACE>;
    )
    ZMK_MACRO(lm_come,
        wait-ms = <MACRO_WAIT>;
        tap-ms = <MACRO_TAP>;
        bindings = <&kp C &kp A &kp M &kp E &kp SPACE>;
    )
    ZMK_MACRO(lsm_come,
        wait-ms = <MACRO_WAIT>;
        tap-ms = <MACRO_TAP>;
        bindings = <&sk LSHIFT &kp C &kp A &kp M &kp E &kp SPACE>;
    )
    ZMK_MACRO(rm_come,
        wait-ms = <MACRO_WAIT>;
        tap-ms = <MACRO_TAP>;
        bindings = <&kp C &kp O &kp M &kp I &kp N &kp G &kp SPACE>;
    )
    ZMK_MACRO(rsm_come,
        wait-ms = <MACRO_WAIT>;
        tap-ms = <MACRO_TAP>;
        bindings = <&sk LSHIFT &kp C &kp O &kp M &kp I &kp N &kp G &kp SPACE>;
    )
    ZMK_MACRO(spm_even,
        wait-ms = <MACRO_WAIT>;
        tap-ms = <MACRO_TAP>;
        bindings = <&kp E &kp V &kp E &kp N &kp SPACE>;
    )
    ZMK_MACRO(shm_even,
        wait-ms = <MACRO_WAIT>;
        tap-ms = <MACRO_TAP>;
        bindings = <&sk LSHIFT &kp E &kp V &kp E &kp N &kp SPACE>;
    )
    ZMK_MACRO(spm_from,
        wait-ms = <MACRO_WAIT>;
        tap-ms = <MACRO_TAP>;
        bindings = <&kp F &kp R &kp O &kp M &kp SPACE>;
    )
    ZMK_MACRO(shm_from,
        wait-ms = <MACRO_WAIT>;
        tap-ms = <MACRO_TAP>;
        bindings = <&sk LSHIFT &kp F &kp R &kp O &kp M &kp SPACE>;
    )
    ZMK_MACRO(spm_give,
        wait-ms = <MACRO_WAIT>;
        tap-ms = <MACRO_TAP>;
        bindings = <&kp G &kp I &kp V &kp E &kp SPACE>;
    )
    ZMK_MACRO(shm_give,
        wait-ms = <MACRO_WAIT>;
        tap-ms = <MACRO_TAP>;
        bindings = <&sk LSHIFT &kp G &kp I &kp V &kp E &kp SPACE>;
    )
    ZMK_MACRO(lm_give,
        wait-ms = <MACRO_WAIT>;
        tap-ms = <MACRO_TAP>;
        bindings = <&kp G &kp A &kp V &kp E &kp SPACE>;
    )
    ZMK_MACRO(lsm_give,
        wait-ms = <MACRO_WAIT>;
        tap-ms = <MACRO_TAP>;
        bindings = <&sk LSHIFT &kp G &kp A &kp V &kp E &kp SPACE>;
    )
    ZMK_MACRO(rm_give,
        wait-ms = <MACRO_WAIT>;
        tap-ms = <MACRO_TAP>;
        bindings = <&kp G &kp I &kp V &kp I &kp N &kp G &kp SPACE>;
    )
    ZMK_MACRO(rsm_give,
        wait-ms = <MACRO_WAIT>;
        tap-ms = <MACRO_TAP>;
        bindings = <&sk LSHIFT &kp G &kp I &kp V &kp I &kp N &kp G &kp SPACE>;
    )
    ZMK_MACRO(spm_good,
        wait-ms = <MACRO_WAIT>;
        tap-ms = <MACRO_TAP>;
        bindings = <&kp G &kp O &kp O &kp D &kp SPACE>;
    )
    ZMK_MACRO(shm_good,
        wait-ms = <MACRO_WAIT>;
        tap-ms = <MACRO_TAP>;
        bindings = <&sk LSHIFT &kp G &kp O &kp O &kp D &kp SPACE>;
    )
    ZMK_MACRO(spm_have,
        wait-ms = <MACRO_WAIT>;
        tap-ms = <MACRO_TAP>;
        bindings = <&kp H &kp A &kp V &kp E &kp SPACE>;
    )
    ZMK_MACRO(shm_have,
        wait-ms = <MACRO_WAIT>;
        tap-ms = <MACRO_TAP>;
        bindings = <&sk LSHIFT &kp H &kp A &kp V &kp E &kp SPACE>;
    )
    ZMK_MACRO(lm_have,
        wait-ms = <MACRO_WAIT>;
        tap-ms = <MACRO_TAP>;
        bindings = <&kp H &kp A &kp D &kp SPACE>;
    )
    ZMK_MACRO(lsm_have,
        wait-ms = <MACRO_WAIT>;
        tap-ms = <MACRO_TAP>;
        bindings = <&sk LSHIFT &kp H &kp A &kp D &kp SPACE>;
    )
    ZMK_MACRO(rm_have,
        wait-ms = <MACRO_WAIT>;
        tap-ms = <MACRO_TAP>;
        bindings = <&kp H &kp A &kp V &kp I &kp N &kp G &kp SPACE>;
    )
    ZMK_MACRO(rsm_have,
        wait-ms = <MACRO_WAIT>;
        tap-ms = <MACRO_TAP>;
        bindings = <&sk LSHIFT &kp H &kp A &kp V &kp I &kp N &kp G &kp SPACE>;
    )
    ZMK_MACRO(spm_into,
        wait-ms = <MACRO_WAIT>;
        tap-ms = <MACRO_TAP>;
        bindings = <&kp I &kp N &kp T &kp O &kp SPACE>;
    )
    ZMK_MACRO(shm_into,
        wait-ms = <MACRO_WAIT>;
        tap-ms = <MACRO_TAP>;
        bindings = <&sk LSHIFT &kp I &kp N &kp T &kp O &kp SPACE>;
    )
    ZMK_MACRO(spm_just,
        wait-ms = <MACRO_WAIT>;
        tap-ms = <MACRO_TAP>;
        bindings = <&kp J &kp U &kp S &kp T &kp SPACE>;
    )
    ZMK_MACRO(shm_just,
        wait-ms = <MACRO_WAIT>;
        tap-ms = <MACRO_TAP>;
        bindings = <&sk LSHIFT &kp J &kp U &kp S &kp T &kp SPACE>;
    )
    ZMK_MACRO(spm_know,
        wait-ms = <MACRO_WAIT>;
        tap-ms = <MACRO_TAP>;
        bindings = <&kp K &kp N &kp O &kp W &kp SPACE>;
    )
    ZMK_MACRO(shm_know,
        wait-ms = <MACRO_WAIT>;
        tap-ms = <MACRO_TAP>;
        bindings = <&sk LSHIFT &kp K &kp N &kp O &kp W &kp SPACE>;
    )
    ZMK_MACRO(lm_know,
        wait-ms = <MACRO_WAIT>;
        tap-ms = <MACRO_TAP>;
        bindings = <&kp K &kp N &kp E &kp W &kp SPACE>;
    )
    ZMK_MACRO(lsm_know,
        wait-ms = <MACRO_WAIT>;
        tap-ms = <MACRO_TAP>;
        bindings = <&sk LSHIFT &kp K &kp N &kp E &kp W &kp SPACE>;
    )
    ZMK_MACRO(rm_know,
        wait-ms = <MACRO_WAIT>;
        tap-ms = <MACRO_TAP>;
        bindings = <&kp K &kp N &kp O &kp W &kp S &kp SPACE>;
    )
    ZMK_MACRO(rsm_know,
        wait-ms = <MACRO_WAIT>;
        tap-ms = <MACRO_TAP>;
        bindings = <&sk LSHIFT &kp K &kp N &kp O &kp W &kp S &kp SPACE>;
    )
    ZMK_MACRO(spm_like,
        wait-ms = <MACRO_WAIT>;
        tap-ms = <MACRO_TAP>;
        bindings = <&kp L &kp I &kp K &kp E &kp SPACE>;
    )
    ZMK_MACRO(shm_like,
        wait-ms = <MACRO_WAIT>;
        tap-ms = <MACRO_TAP>;
        bindings = <&sk LSHIFT &kp L &kp I &kp K &kp E &kp SPACE>;
    )
    ZMK_MACRO(lm_like,
        wait-ms = <MACRO_WAIT>;
        tap-ms = <MACRO_TAP>;
        bindings = <&kp L &kp I &kp K &kp E &kp D &kp SPACE>;
    )
    ZMK_MACRO(lsm_like,
        wait-ms = <MACRO_WAIT>;
        tap-ms = <MACRO_TAP>;
        bindings = <&sk LSHIFT &kp L &kp I &kp K &kp E &kp D &kp SPACE>;
    )
    ZMK_MACRO(rm_like,
        wait-ms = <MACRO_WAIT>;
        tap-ms = <MACRO_TAP>;
        bindings = <&kp L &kp I &kp K &kp E &kp S &kp SPACE>;
    )
    ZMK_MACRO(rsm_like,
        wait-ms = <MACRO_WAIT>;
        tap-ms = <MACRO_TAP>;
        bindings = <&sk LSHIFT &kp L &kp I &kp K &kp E &kp S &kp SPACE>;
    )
    ZMK_MACRO(spm_look,
        wait-ms = <MACRO_WAIT>;
        tap-ms = <MACRO_TAP>;
        bindings = <&kp L &kp O &kp O &kp K &kp SPACE>;
    )
    ZMK_MACRO(shm_look,
        wait-ms = <MACRO_WAIT>;
        tap-ms = <MACRO_TAP>;
        bindings = <&sk LSHIFT &kp L &kp O &kp O &kp K &kp SPACE>;
    )
    ZMK_MACRO(lm_look,
        wait-ms = <MACRO_WAIT>;
        tap-ms = <MACRO_TAP>;
        bindings = <&kp L &kp O &kp O &kp K &kp E &kp D &kp SPACE>;
    )
    ZMK_MACRO(lsm_look,
        wait-ms = <MACRO_WAIT>;
        tap-ms = <MACRO_TAP>;
        bindings = <&sk LSHIFT &kp L &kp O &kp O &kp K &kp E &kp D &kp SPACE>;
    )
    ZMK_MACRO(rm_look,
        wait-ms = <MACRO_WAIT>;
        tap-ms = <MACRO_TAP>;
        bindings = <&kp L &kp O &kp O &kp K &kp I &kp N &kp G &kp SPACE>;
    )
    ZMK_MACRO(rsm_look,
        wait-ms = <MACRO_WAIT>;
        tap-ms = <MACRO_TAP>;
        bindings = <&sk LSHIFT &kp L &kp O &kp O &kp K &kp I &kp N &kp G &kp SPACE>;
    )
    ZMK_MACRO(spm_make,
        wait-ms = <MACRO_WAIT>;
        tap-ms = <MACRO_TAP>;
        bindings = <&kp M &kp A &kp K &kp E &kp SPACE>;
    )
    ZMK_MACRO(shm_make,
        wait-ms = <MACRO_WAIT>;
        tap-ms = <MACRO_TAP>;
        bindings = <&sk LSHIFT &kp M &kp A &kp K &kp E &kp SPACE>;
    )
    ZMK_MACRO(lm_make,
        wait-ms = <MACRO_WAIT>;
        tap-ms = <MACRO_TAP>;
        bindings = <&kp M &kp A &kp D &kp E &kp SPACE>;
    )
    ZMK_MACRO(lsm_make,
        wait-ms = <MACRO_WAIT>;
        tap-ms = <MACRO_TAP>;
        bindings = <&sk LSHIFT &kp M &kp A &kp D &kp E &kp SPACE>;
    )
    ZMK_MACRO(rm_make,
        wait-ms = <MACRO_WAIT>;
        tap-ms = <MACRO_TAP>;
        bindings = <&kp M &kp A &kp K &kp I &kp N &kp G &kp SPACE>;
    )
    ZMK_MACRO(rsm_make,
        wait-ms = <MACRO_WAIT>;
        tap-ms = <MACRO_TAP>;
        bindings = <&sk LSHIFT &kp M &kp A &kp K &kp I &kp N &kp G &kp SPACE>;
    )
    ZMK_MACRO(spm_most,
        wait-ms = <MACRO_WAIT>;
        tap-ms = <MACRO_TAP>;
        bindings = <&kp M &kp O &kp S &kp T &kp SPACE>;
    )
    ZMK_MACRO(shm_most,
        wait-ms = <MACRO_WAIT>;
        tap-ms = <MACRO_TAP>;
        bindings = <&sk LSHIFT &kp M &kp O &kp S &kp T &kp SPACE>;
    )
    ZMK_MACRO(spm_only,
        wait-ms = <MACRO_WAIT>;
        tap-ms = <MACRO_TAP>;
        bindings = <&kp O &kp N &kp L &kp Y &kp SPACE>;
    )
    ZMK_MACRO(shm_only,
        wait-ms = <MACRO_WAIT>;
        tap-ms = <MACRO_TAP>;
        bindings = <&sk LSHIFT &kp O &kp N &kp L &kp Y &kp SPACE>;
    )
    ZMK_MACRO(spm_over,
        wait-ms = <MACRO_WAIT>;
        tap-ms = <MACRO_TAP>;
        bindings = <&kp O &kp V &kp E &kp R &kp SPACE>;
    )
    ZMK_MACRO(shm_over,
        wait-ms = <MACRO_WAIT>;
        tap-ms = <MACRO_TAP>;
        bindings = <&sk LSHIFT &kp O &kp V &kp E &kp R &kp SPACE>;
    )
    ZMK_MACRO(spm_some,
        wait-ms = <MACRO_WAIT>;
        tap-ms = <MACRO_TAP>;
        bindings = <&kp S &kp O &kp M &kp E &kp SPACE>;
    )
    ZMK_MACRO(shm_some,
        wait-ms = <MACRO_WAIT>;
        tap-ms = <MACRO_TAP>;
        bindings = <&sk LSHIFT &kp S &kp O &kp M &kp E &kp SPACE>;
    )
    ZMK_MACRO(spm_take,
        wait-ms = <MACRO_WAIT>;
        tap-ms = <MACRO_TAP>;
        bindings = <&kp T &kp A &kp K &kp E &kp SPACE>;
    )
    ZMK_MACRO(shm_take,
        wait-ms = <MACRO_WAIT>;
        tap-ms = <MACRO_TAP>;
        bindings = <&sk LSHIFT &kp T &kp A &kp K &kp E &kp SPACE>;
    )
    ZMK_MACRO(lm_take,
        wait-ms = <MACRO_WAIT>;
        tap-ms = <MACRO_TAP>;
        bindings = <&kp T &kp O &kp O &kp K &kp SPACE>;
    )
    ZMK_MACRO(lsm_take,
        wait-ms = <MACRO_WAIT>;
        tap-ms = <MACRO_TAP>;
        bindings = <&sk LSHIFT &kp T &kp O &kp O &kp K &kp SPACE>;
    )
    ZMK_MACRO(rm_take,
        wait-ms = <MACRO_WAIT>;
        tap-ms = <MACRO_TAP>;
        bindings = <&kp T &kp A &kp K &kp I &kp N &kp G &kp SPACE>;
    )
    ZMK_MACRO(rsm_take,
        wait-ms = <MACRO_WAIT>;
        tap-ms = <MACRO_TAP>;
        bindings = <&sk LSHIFT &kp T &kp A &kp K &kp I &kp N &kp G &kp SPACE>;
    )
    ZMK_MACRO(spm_than,
        wait-ms = <MACRO_WAIT>;
        tap-ms = <MACRO_TAP>;
        bindings = <&kp T &kp H &kp A &kp N &kp SPACE>;
    )
    ZMK_MACRO(shm_than,
        wait-ms = <MACRO_WAIT>;
        tap-ms = <MACRO_TAP>;
        bindings = <&sk LSHIFT &kp T &kp H &kp A &kp N &kp SPACE>;
    )
    ZMK_MACRO(spm_that,
        wait-ms = <MACRO_WAIT>;
        tap-ms = <MACRO_TAP>;
        bindings = <&kp T &kp H &kp A &kp T &kp SPACE>;
    )
    ZMK_MACRO(shm_that,
        wait-ms = <MACRO_WAIT>;
        tap-ms = <MACRO_TAP>;
        bindings = <&sk LSHIFT &kp T &kp H &kp A &kp T &kp SPACE>;
    )
    ZMK_MACRO(lm_that,
        wait-ms = <MACRO_WAIT>;
        tap-ms = <MACRO_TAP>;
        bindings = <&kp T &kp H &kp O &kp S &kp E &kp SPACE>;
    )
    ZMK_MACRO(lsm_that,
        wait-ms = <MACRO_WAIT>;
        tap-ms = <MACRO_TAP>;
        bindings = <&sk LSHIFT &kp T &kp H &kp O &kp S &kp E &kp SPACE>;
    )
    ZMK_MACRO(spm_them,
        wait-ms = <MACRO_WAIT>;
        tap-ms = <MACRO_TAP>;
        bindings = <&kp T &kp H &kp E &kp M &kp SPACE>;
    )
    ZMK_MACRO(shm_them,
        wait-ms = <MACRO_WAIT>;
        tap-ms = <MACRO_TAP>;
        bindings = <&sk LSHIFT &kp T &kp H &kp E &kp M &kp SPACE>;
    )
    ZMK_MACRO(spm_then,
        wait-ms = <MACRO_WAIT>;
        tap-ms = <MACRO_TAP>;
        bindings = <&kp T &kp H &kp E &kp N &kp SPACE>;
    )
    ZMK_MACRO(shm_then,
        wait-ms = <MACRO_WAIT>;
        tap-ms = <MACRO_TAP>;
        bindings = <&sk LSHIFT &kp T &kp H &kp E &kp N &kp SPACE>;
    )
    ZMK_MACRO(spm_they,
        wait-ms = <MACRO_WAIT>;
        tap-ms = <MACRO_TAP>;
        bindings = <&kp T &kp H &kp E &kp Y &kp SPACE>;
    )
    ZMK_MACRO(shm_they,
        wait-ms = <MACRO_WAIT>;
        tap-ms = <MACRO_TAP>;
        bindings = <&sk LSHIFT &kp T &kp H &kp E &kp Y &kp SPACE>;
    )
    ZMK_MACRO(lm_they,
        wait-ms = <MACRO_WAIT>;
        tap-ms = <MACRO_TAP>;
        bindings = <&kp T &kp H &kp E &kp I &kp R &kp SPACE>;
    )
    ZMK_MACRO(lsm_they,
        wait-ms = <MACRO_WAIT>;
        tap-ms = <MACRO_TAP>;
        bindings = <&sk LSHIFT &kp T &kp H &kp E &kp I &kp R &kp SPACE>;
    )
    ZMK_MACRO(rm_they,
        wait-ms = <MACRO_WAIT>;
        tap-ms = <MACRO_TAP>;
        bindings = <&kp T &kp H &kp E &kp I &kp R &kp S &kp SPACE>;
    )
    ZMK_MACRO(rsm_they,
        wait-ms = <MACRO_WAIT>;
        tap-ms = <MACRO_TAP>;
        bindings = <&sk LSHIFT &kp T &kp H &kp E &kp I &kp R &kp S &kp SPACE>;
    )
    ZMK_MACRO(spm_theySQTre,
        wait-ms = <MACRO_WAIT>;
        tap-ms = <MACRO_TAP>;
        bindings = <&kp T &kp H &kp E &kp Y &kp SQT &kp R &kp E &kp SPACE>;
    )
    ZMK_MACRO(shm_theySQTre,
        wait-ms = <MACRO_WAIT>;
        tap-ms = <MACRO_TAP>;
        bindings = <&sk LSHIFT &kp T &kp H &kp E &kp Y &kp SQT &kp R &kp E &kp SPACE>;
    )
    ZMK_MACRO(spm_theySQTve,
        wait-ms = <MACRO_WAIT>;
        tap-ms = <MACRO_TAP>;
        bindings = <&kp T &kp H &kp E &kp Y &kp SQT &kp V &kp E &kp SPACE>;
    )
    ZMK_MACRO(shm_theySQTve,
        wait-ms = <MACRO_WAIT>;
        tap-ms = <MACRO_TAP>;
        bindings = <&sk LSHIFT &kp T &kp H &kp E &kp Y &kp SQT &kp V &kp E &kp SPACE>;
    )
    ZMK_MACRO(spm_theySQTll,
        wait-ms = <MACRO_WAIT>;
        tap-ms = <MACRO_TAP>;
        bindings = <&kp T &kp H &kp E &kp Y &kp SQT &kp L &kp L &kp SPACE>;
    )
    ZMK_MACRO(shm_theySQTll,
        wait-ms = <MACRO_WAIT>;
        tap-ms = <MACRO_TAP>;
        bindings = <&sk LSHIFT &kp T &kp H &kp E &kp Y &kp SQT &kp L &kp L &kp SPACE>;
    )
    ZMK_MACRO(spm_this,
        wait-ms = <MACRO_WAIT>;
        tap-ms = <MACRO_TAP>;
        bindings = <&kp T &kp H &kp I &kp S &kp SPACE>;
    )
    ZMK_MACRO(shm_this,
        wait-ms = <MACRO_WAIT>;
        tap-ms = <MACRO_TAP>;
        bindings = <&sk LSHIFT &kp T &kp H &kp I &kp S &kp SPACE>;
    )
    ZMK_MACRO(lm_this,
        wait-ms = <MACRO_WAIT>;
        tap-ms = <MACRO_TAP>;
        bindings = <&kp T &kp H &kp E &kp S &kp E &kp SPACE>;
    )
    ZMK_MACRO(lsm_this,
        wait-ms = <MACRO_WAIT>;
        tap-ms = <MACRO_TAP>;
        bindings = <&sk LSHIFT &kp T &kp H &kp E &kp S &kp E &kp SPACE>;
    )
    ZMK_MACRO(spm_time,
        wait-ms = <MACRO_WAIT>;
        tap-ms = <MACRO_TAP>;
        bindings = <&kp T &kp I &kp M &kp E &kp SPACE>;
    )
    ZMK_MACRO(shm_time,
        wait-ms = <MACRO_WAIT>;
        tap-ms = <MACRO_TAP>;
        bindings = <&sk LSHIFT &kp T &kp I &kp M &kp E &kp SPACE>;
    )
    ZMK_MACRO(lm_time,
        wait-ms = <MACRO_WAIT>;
        tap-ms = <MACRO_TAP>;
        bindings = <&kp T &kp I &kp M &kp E &kp S &kp SPACE>;
    )
    ZMK_MACRO(lsm_time,
        wait-ms = <MACRO_WAIT>;
        tap-ms = <MACRO_TAP>;
        bindings = <&sk LSHIFT &kp T &kp I &kp M &kp E &kp S &kp SPACE>;
    )
    ZMK_MACRO(spm_want,
        wait-ms = <MACRO_WAIT>;
        tap-ms = <MACRO_TAP>;
        bindings = <&kp W &kp A &kp N &kp T &kp SPACE>;
    )
    ZMK_MACRO(shm_want,
        wait-ms = <MACRO_WAIT>;
        tap-ms = <MACRO_TAP>;
        bindings = <&sk LSHIFT &kp W &kp A &kp N &kp T &kp SPACE>;
    )
    ZMK_MACRO(lm_want,
        wait-ms = <MACRO_WAIT>;
        tap-ms = <MACRO_TAP>;
        bindings = <&kp W &kp A &kp N &kp T &kp E &kp D &kp SPACE>;
    )
    ZMK_MACRO(lsm_want,
        wait-ms = <MACRO_WAIT>;
        tap-ms = <MACRO_TAP>;
        bindings = <&sk LSHIFT &kp W &kp A &kp N &kp T &kp E &kp D &kp SPACE>;
    )
    ZMK_MACRO(rm_want,
        wait-ms = <MACRO_WAIT>;
        tap-ms = <MACRO_TAP>;
        bindings = <&kp W &kp A &kp N &kp T &kp S &kp SPACE>;
    )
    ZMK_MACRO(rsm_want,
        wait-ms = <MACRO_WAIT>;
        tap-ms = <MACRO_TAP>;
        bindings = <&sk LSHIFT &kp W &kp A &kp N &kp T &kp S &kp SPACE>;
    )
    ZMK_MACRO(spm_well,
        wait-ms = <MACRO_WAIT>;
        tap-ms = <MACRO_TAP>;
        bindings = <&kp W &kp E &kp L &kp L &kp SPACE>;
    )
    ZMK_MACRO(shm_well,
        wait-ms = <MACRO_WAIT>;
        tap-ms = <MACRO_TAP>;
        bindings = <&sk LSHIFT &kp W &kp E &kp L &kp L &kp SPACE>;
    )
    ZMK_MACRO(spm_what,
        wait-ms = <MACRO_WAIT>;
        tap-ms = <MACRO_TAP>;
        bindings = <&kp W &kp H &kp A &kp T &kp SPACE>;
    )
    ZMK_MACRO(shm_what,
        wait-ms = <MACRO_WAIT>;
        tap-ms = <MACRO_TAP>;
        bindings = <&sk LSHIFT &kp W &kp H &kp A &kp T &kp SPACE>;
    )
    ZMK_MACRO(spm_when,
        wait-ms = <MACRO_WAIT>;
        tap-ms = <MACRO_TAP>;
        bindings = <&kp W &kp H &kp E &kp N &kp SPACE>;
    )
    ZMK_MACRO(shm_when,
        wait-ms = <MACRO_WAIT>;
        tap-ms = <MACRO_TAP>;
        bindings = <&sk LSHIFT &kp W &kp H &kp E &kp N &kp SPACE>;
    )
    ZMK_MACRO(spm_will,
        wait-ms = <MACRO_WAIT>;
        tap-ms = <MACRO_TAP>;
        bindings = <&kp W &kp I &kp L &kp L &kp SPACE>;
    )
    ZMK_MACRO(shm_will,
        wait-ms = <MACRO_WAIT>;
        tap-ms = <MACRO_TAP>;
        bindings = <&sk LSHIFT &kp W &kp I &kp L &kp L &kp SPACE>;
    )
    ZMK_MACRO(lm_will,
        wait-ms = <MACRO_WAIT>;
        tap-ms = <MACRO_TAP>;
        bindings = <&kp W &kp O &kp N &kp SQT &kp T &kp SPACE>;
    )
    ZMK_MACRO(lsm_will,
        wait-ms = <MACRO_WAIT>;
        tap-ms = <MACRO_TAP>;
        bindings = <&sk LSHIFT &kp W &kp O &kp N &kp SQT &kp T &kp SPACE>;
    )
    ZMK_MACRO(spm_would,
        wait-ms = <MACRO_WAIT>;
        tap-ms = <MACRO_TAP>;
        bindings = <&kp W &kp O &kp U &kp L &kp D &kp SPACE>;
    )
    ZMK_MACRO(shm_would,
        wait-ms = <MACRO_WAIT>;
        tap-ms = <MACRO_TAP>;
        bindings = <&sk LSHIFT &kp W &kp O &kp U &kp L &kp D &kp SPACE>;
    )
    ZMK_MACRO(lm_would,
        wait-ms = <MACRO_WAIT>;
        tap-ms = <MACRO_TAP>;
        bindings = <&kp W &kp O &kp U &kp L &kp D &kp N &kp SQT &kp T &kp SPACE>;
    )
    ZMK_MACRO(lsm_would,
        wait-ms = <MACRO_WAIT>;
        tap-ms = <MACRO_TAP>;
        bindings = <&sk LSHIFT &kp W &kp O &kp U &kp L &kp D &kp N &kp SQT &kp T &kp SPACE>;
    )
    ZMK_MACRO(spm_with,
        wait-ms = <MACRO_WAIT>;
        tap-ms = <MACRO_TAP>;
        bindings = <&kp W &kp I &kp T &kp H &kp SPACE>;
    )
    ZMK_MACRO(shm_with,
        wait-ms = <MACRO_WAIT>;
        tap-ms = <MACRO_TAP>;
        bindings = <&sk LSHIFT &kp W &kp I &kp T &kp H &kp SPACE>;
    )
    ZMK_MACRO(spm_work,
        wait-ms = <MACRO_WAIT>;
        tap-ms = <MACRO_TAP>;
        bindings = <&kp W &kp O &kp R &kp K &kp SPACE>;
    )
    ZMK_MACRO(shm_work,
        wait-ms = <MACRO_WAIT>;
        tap-ms = <MACRO_TAP>;
        bindings = <&sk LSHIFT &kp W &kp O &kp R &kp K &kp SPACE>;
    )
    ZMK_MACRO(lm_work,
        wait-ms = <MACRO_WAIT>;
        tap-ms = <MACRO_TAP>;
        bindings = <&kp W &kp O &kp R &kp K &kp E &kp D &kp SPACE>;
    )
    ZMK_MACRO(lsm_work,
        wait-ms = <MACRO_WAIT>;
        tap-ms = <MACRO_TAP>;
        bindings = <&sk LSHIFT &kp W &kp O &kp R &kp K &kp E &kp D &kp SPACE>;
    )
    ZMK_MACRO(rm_work,
        wait-ms = <MACRO_WAIT>;
        tap-ms = <MACRO_TAP>;
        bindings = <&kp W &kp O &kp R &kp K &kp I &kp N &kp G &kp SPACE>;
    )
    ZMK_MACRO(rsm_work,
        wait-ms = <MACRO_WAIT>;
        tap-ms = <MACRO_TAP>;
        bindings = <&sk LSHIFT &kp W &kp O &kp R &kp K &kp I &kp N &kp G &kp SPACE>;
    )
    ZMK_MACRO(spm_year,
        wait-ms = <MACRO_WAIT>;
        tap-ms = <MACRO_TAP>;
        bindings = <&kp Y &kp E &kp A &kp R &kp SPACE>;
    )
    ZMK_MACRO(shm_year,
        wait-ms = <MACRO_WAIT>;
        tap-ms = <MACRO_TAP>;
        bindings = <&sk LSHIFT &kp Y &kp E &kp A &kp R &kp SPACE>;
    )
    ZMK_MACRO(lm_year,
        wait-ms = <MACRO_WAIT>;
        tap-ms = <MACRO_TAP>;
        bindings = <&kp Y &kp E &kp A &kp R &kp S &kp SPACE>;
    )
    ZMK_MACRO(lsm_year,
        wait-ms = <MACRO_WAIT>;
        tap-ms = <MACRO_TAP>;
        bindings = <&sk LSHIFT &kp Y &kp E &kp A &kp R &kp S &kp SPACE>;
    )
    ZMK_MACRO(spm_about,
        wait-ms = <MACRO_WAIT>;
        tap-ms = <MACRO_TAP>;
        bindings = <&kp A &kp B &kp O &kp U &kp T &kp SPACE>;
    )
    ZMK_MACRO(shm_about,
        wait-ms = <MACRO_WAIT>;
        tap-ms = <MACRO_TAP>;
        bindings = <&sk LSHIFT &kp A &kp B &kp O &kp U &kp T &kp SPACE>;
    )
    ZMK_MACRO(spm_after,
        wait-ms = <MACRO_WAIT>;
        tap-ms = <MACRO_TAP>;
        bindings = <&kp A &kp F &kp T &kp E &kp R &kp SPACE>;
    )
    ZMK_MACRO(shm_after,
        wait-ms = <MACRO_WAIT>;
        tap-ms = <MACRO_TAP>;
        bindings = <&sk LSHIFT &kp A &kp F &kp T &kp E &kp R &kp SPACE>;
    )
    ZMK_MACRO(spm_first,
        wait-ms = <MACRO_WAIT>;
        tap-ms = <MACRO_TAP>;
        bindings = <&kp F &kp I &kp R &kp S &kp T &kp SPACE>;
    )
    ZMK_MACRO(shm_first,
        wait-ms = <MACRO_WAIT>;
        tap-ms = <MACRO_TAP>;
        bindings = <&sk LSHIFT &kp F &kp I &kp R &kp S &kp T &kp SPACE>;
    )
    ZMK_MACRO(spm_other,
        wait-ms = <MACRO_WAIT>;
        tap-ms = <MACRO_TAP>;
        bindings = <&kp O &kp T &kp H &kp E &kp R &kp SPACE>;
    )
    ZMK_MACRO(shm_other,
        wait-ms = <MACRO_WAIT>;
        tap-ms = <MACRO_TAP>;
        bindings = <&sk LSHIFT &kp O &kp T &kp H &kp E &kp R &kp SPACE>;
    )
    ZMK_MACRO(spm_there,
        wait-ms = <MACRO_WAIT>;
        tap-ms = <MACRO_TAP>;
        bindings = <&kp T &kp H &kp E &kp R &kp E &kp SPACE>;
    )
    ZMK_MACRO(shm_there,
        wait-ms = <MACRO_WAIT>;
        tap-ms = <MACRO_TAP>;
        bindings = <&sk LSHIFT &kp T &kp H &kp E &kp R &kp E &kp SPACE>;
    )
    ZMK_MACRO(spm_think,
        wait-ms = <MACRO_WAIT>;
        tap-ms = <MACRO_TAP>;
        bindings = <&kp T &kp H &kp I &kp N &kp K &kp SPACE>;
    )
    ZMK_MACRO(shm_think,
        wait-ms = <MACRO_WAIT>;
        tap-ms = <MACRO_TAP>;
        bindings = <&sk LSHIFT &kp T &kp H &kp I &kp N &kp K &kp SPACE>;
    )
    ZMK_MACRO(lm_think,
        wait-ms = <MACRO_WAIT>;
        tap-ms = <MACRO_TAP>;
        bindings = <&kp T &kp H &kp O &kp U &kp G &kp H &kp T &kp SPACE>;
    )
    ZMK_MACRO(lsm_think,
        wait-ms = <MACRO_WAIT>;
        tap-ms = <MACRO_TAP>;
        bindings = <&sk LSHIFT &kp T &kp H &kp O &kp U &kp G &kp H &kp T &kp SPACE>;
    )
    ZMK_MACRO(rm_think,
        wait-ms = <MACRO_WAIT>;
        tap-ms = <MACRO_TAP>;
        bindings = <&kp T &kp H &kp I &kp N &kp K &kp I &kp N &kp G &kp SPACE>;
    )
    ZMK_MACRO(rsm_think,
        wait-ms = <MACRO_WAIT>;
        tap-ms = <MACRO_TAP>;
        bindings = <&sk LSHIFT &kp T &kp H &kp I &kp N &kp K &kp I &kp N &kp G &kp SPACE>;
    )
    ZMK_MACRO(spm_which,
        wait-ms = <MACRO_WAIT>;
        tap-ms = <MACRO_TAP>;
        bindings = <&kp W &kp H &kp I &kp C &kp H &kp SPACE>;
    )
    ZMK_MACRO(shm_which,
        wait-ms = <MACRO_WAIT>;
        tap-ms = <MACRO_TAP>;
        bindings = <&sk LSHIFT &kp W &kp H &kp I &kp C &kp H &kp SPACE>;
    )
    ZMK_MACRO(spm_people,
        wait-ms = <MACRO_WAIT>;
        tap-ms = <MACRO_TAP>;
        bindings = <&kp P &kp E &kp O &kp P &kp L &kp E &kp SPACE>;
    )
    ZMK_MACRO(shm_people,
        wait-ms = <MACRO_WAIT>;
        tap-ms = <MACRO_TAP>;
        bindings = <&sk LSHIFT &kp P &kp E &kp O &kp P &kp L &kp E &kp SPACE>;
    )
    ZMK_MACRO(spm_because,
        wait-ms = <MACRO_WAIT>;
        tap-ms = <MACRO_TAP>;
        bindings = <&kp B &kp E &kp C &kp A &kp U &kp S &kp E &kp SPACE>;
    )
    ZMK_MACRO(shm_because,
        wait-ms = <MACRO_WAIT>;
        tap-ms = <MACRO_TAP>;
        bindings = <&sk LSHIFT &kp B &kp E &kp C &kp A &kp U &kp S &kp E &kp SPACE>;
    )

    // MACROS END
  };
  combos {
    compatible = "zmk,combos";
    combo_system {
      timeout-ms = <100>;
      key-positions = <0 20>;
      bindings = <&tog L_SYS>;
    };
    combo_comma {
      timeout-ms = <COMBO_TIMEOUT>;
      key-positions = <P_S P_COMMA P_SPC>;
      bindings = <&m_comma>;
    };
    combo_dot {
      timeout-ms = <COMBO_TIMEOUT>;
      key-positions = <P_S P_DOT P_SPC>;
      bindings = <&m_dot>;
    };
    combo_ques {
      timeout-ms = <COMBO_TIMEOUT>;
      key-positions = <P_S P_SQT P_SPC>;
      bindings = <&m_ques>;
    };
    // COMBOS START
    combo_spm_a {
      timeout-ms = <COMBO_TIMEOUT>;
      key-positions = <P_A P_R P_SPC>;
      bindings = <&spm_a>;
    };
    combo_shm_a {
      timeout-ms = <COMBO_TIMEOUT>;
      key-positions = <P_A P_R P_SHFT>;
      bindings = <&shm_a>;
    };
    combo_spm_I {
      timeout-ms = <COMBO_TIMEOUT>;
      key-positions = <P_E P_I P_SPC>;
      bindings = <&spm_I>;
    };
    combo_shm_I {
      timeout-ms = <COMBO_TIMEOUT>;
      key-positions = <P_E P_I P_SHFT>;
      bindings = <&shm_I>;
    };
    combo_spm_ISQTm {
      timeout-ms = <COMBO_TIMEOUT>;
      key-positions = <P_I P_M P_SPC>;
      bindings = <&spm_ISQTm>;
    };
    combo_shm_ISQTm {
      timeout-ms = <COMBO_TIMEOUT>;
      key-positions = <P_I P_M P_SHFT>;
      bindings = <&shm_ISQTm>;
    };
    combo_lm_ISQTm {
      timeout-ms = <COMBO_TIMEOUT>;
      key-positions = <P_I P_M P_LALT>;
      bindings = <&lm_ISQTm>;
    };
    combo_lsm_ISQTm {
      timeout-ms = <COMBO_TIMEOUT>;
      key-positions = <P_I P_M P_LALT P_SHFT>;
      bindings = <&lsm_ISQTm>;
    };
    combo_rm_ISQTm {
      timeout-ms = <COMBO_TIMEOUT>;
      key-positions = <P_I P_M P_RALT>;
      bindings = <&rm_ISQTm>;
    };
    combo_rsm_ISQTm {
      timeout-ms = <COMBO_TIMEOUT>;
      key-positions = <P_I P_M P_RALT P_SPC>;
      bindings = <&rsm_ISQTm>;
    };
    combo_spm_ISQTve {
      timeout-ms = <COMBO_TIMEOUT>;
      key-positions = <P_I P_V P_SPC>;
      bindings = <&spm_ISQTve>;
    };
    combo_shm_ISQTve {
      timeout-ms = <COMBO_TIMEOUT>;
      key-positions = <P_I P_V P_SHFT>;
      bindings = <&shm_ISQTve>;
    };
    combo_spm_ISQTll {
      timeout-ms = <COMBO_TIMEOUT>;
      key-positions = <P_I P_L P_SPC>;
      bindings = <&spm_ISQTll>;
    };
    combo_shm_ISQTll {
      timeout-ms = <COMBO_TIMEOUT>;
      key-positions = <P_I P_L P_SHFT>;
      bindings = <&shm_ISQTll>;
    };
    combo_spm_an {
      timeout-ms = <COMBO_TIMEOUT>;
      key-positions = <P_A P_N P_SPC>;
      bindings = <&spm_an>;
    };
    combo_shm_an {
      timeout-ms = <COMBO_TIMEOUT>;
      key-positions = <P_A P_N P_SHFT>;
      bindings = <&shm_an>;
    };
    combo_spm_am {
      timeout-ms = <COMBO_TIMEOUT>;
      key-positions = <P_A P_M P_SPC>;
      bindings = <&spm_am>;
    };
    combo_shm_am {
      timeout-ms = <COMBO_TIMEOUT>;
      key-positions = <P_A P_M P_SHFT>;
      bindings = <&shm_am>;
    };
    combo_spm_as {
      timeout-ms = <COMBO_TIMEOUT>;
      key-positions = <P_A P_S P_SPC>;
      bindings = <&spm_as>;
    };
    combo_shm_as {
      timeout-ms = <COMBO_TIMEOUT>;
      key-positions = <P_A P_S P_SHFT>;
      bindings = <&shm_as>;
    };
    combo_spm_at {
      timeout-ms = <COMBO_TIMEOUT>;
      key-positions = <P_A P_T P_SPC>;
      bindings = <&spm_at>;
    };
    combo_shm_at {
      timeout-ms = <COMBO_TIMEOUT>;
      key-positions = <P_A P_T P_SHFT>;
      bindings = <&shm_at>;
    };
    combo_spm_be {
      timeout-ms = <COMBO_TIMEOUT>;
      key-positions = <P_B P_E P_SPC>;
      bindings = <&spm_be>;
    };
    combo_shm_be {
      timeout-ms = <COMBO_TIMEOUT>;
      key-positions = <P_B P_E P_SHFT>;
      bindings = <&shm_be>;
    };
    combo_spm_by {
      timeout-ms = <COMBO_TIMEOUT>;
      key-positions = <P_B P_Y P_SPC>;
      bindings = <&spm_by>;
    };
    combo_shm_by {
      timeout-ms = <COMBO_TIMEOUT>;
      key-positions = <P_B P_Y P_SHFT>;
      bindings = <&shm_by>;
    };
    combo_spm_do {
      timeout-ms = <COMBO_TIMEOUT>;
      key-positions = <P_D P_O P_SPC>;
      bindings = <&spm_do>;
    };
    combo_shm_do {
      timeout-ms = <COMBO_TIMEOUT>;
      key-positions = <P_D P_O P_SHFT>;
      bindings = <&shm_do>;
    };
    combo_lm_do {
      timeout-ms = <COMBO_TIMEOUT>;
      key-positions = <P_D P_O P_LALT>;
      bindings = <&lm_do>;
    };
    combo_lsm_do {
      timeout-ms = <COMBO_TIMEOUT>;
      key-positions = <P_D P_O P_LALT P_SHFT>;
      bindings = <&lsm_do>;
    };
    combo_rm_do {
      timeout-ms = <COMBO_TIMEOUT>;
      key-positions = <P_D P_O P_RALT>;
      bindings = <&rm_do>;
    };
    combo_rsm_do {
      timeout-ms = <COMBO_TIMEOUT>;
      key-positions = <P_D P_O P_RALT P_SPC>;
      bindings = <&rsm_do>;
    };
    combo_spm_donSQTt {
      timeout-ms = <COMBO_TIMEOUT>;
      key-positions = <P_D P_N P_SPC>;
      bindings = <&spm_donSQTt>;
    };
    combo_shm_donSQTt {
      timeout-ms = <COMBO_TIMEOUT>;
      key-positions = <P_D P_N P_SHFT>;
      bindings = <&shm_donSQTt>;
    };
    combo_lm_donSQTt {
      timeout-ms = <COMBO_TIMEOUT>;
      key-positions = <P_D P_N P_LALT>;
      bindings = <&lm_donSQTt>;
    };
    combo_lsm_donSQTt {
      timeout-ms = <COMBO_TIMEOUT>;
      key-positions = <P_D P_N P_LALT P_SHFT>;
      bindings = <&lsm_donSQTt>;
    };
    combo_spm_go {
      timeout-ms = <COMBO_TIMEOUT>;
      key-positions = <P_G P_O P_SPC>;
      bindings = <&spm_go>;
    };
    combo_shm_go {
      timeout-ms = <COMBO_TIMEOUT>;
      key-positions = <P_G P_O P_SHFT>;
      bindings = <&shm_go>;
    };
    combo_spm_he {
      timeout-ms = <COMBO_TIMEOUT>;
      key-positions = <P_H P_E P_SPC>;
      bindings = <&spm_he>;
    };
    combo_shm_he {
      timeout-ms = <COMBO_TIMEOUT>;
      key-positions = <P_H P_E P_SHFT>;
      bindings = <&shm_he>;
    };
    combo_lm_he {
      timeout-ms = <COMBO_TIMEOUT>;
      key-positions = <P_H P_E P_LALT>;
      bindings = <&lm_he>;
    };
    combo_lsm_he {
      timeout-ms = <COMBO_TIMEOUT>;
      key-positions = <P_H P_E P_LALT P_SHFT>;
      bindings = <&lsm_he>;
    };
    combo_rm_he {
      timeout-ms = <COMBO_TIMEOUT>;
      key-positions = <P_H P_E P_RALT>;
      bindings = <&rm_he>;
    };
    combo_rsm_he {
      timeout-ms = <COMBO_TIMEOUT>;
      key-positions = <P_H P_E P_RALT P_SPC>;
      bindings = <&rsm_he>;
    };
    combo_spm_hi {
      timeout-ms = <COMBO_TIMEOUT>;
      key-positions = <P_H P_I P_SPC>;
      bindings = <&spm_hi>;
    };
    combo_shm_hi {
      timeout-ms = <COMBO_TIMEOUT>;
      key-positions = <P_H P_I P_SHFT>;
      bindings = <&shm_hi>;
    };
    combo_lm_hi {
      timeout-ms = <COMBO_TIMEOUT>;
      key-positions = <P_H P_I P_LALT>;
      bindings = <&lm_hi>;
    };
    combo_lsm_hi {
      timeout-ms = <COMBO_TIMEOUT>;
      key-positions = <P_H P_I P_LALT P_SHFT>;
      bindings = <&lsm_hi>;
    };
    combo_rm_hi {
      timeout-ms = <COMBO_TIMEOUT>;
      key-positions = <P_H P_I P_RALT>;
      bindings = <&rm_hi>;
    };
    combo_rsm_hi {
      timeout-ms = <COMBO_TIMEOUT>;
      key-positions = <P_H P_I P_RALT P_SPC>;
      bindings = <&rsm_hi>;
    };
    combo_spm_if {
      timeout-ms = <COMBO_TIMEOUT>;
      key-positions = <P_I P_F P_SPC>;
      bindings = <&spm_if>;
    };
    combo_shm_if {
      timeout-ms = <COMBO_TIMEOUT>;
      key-positions = <P_I P_F P_SHFT>;
      bindings = <&shm_if>;
    };
    combo_spm_in {
      timeout-ms = <COMBO_TIMEOUT>;
      key-positions = <P_I P_N P_SPC>;
      bindings = <&spm_in>;
    };
    combo_shm_in {
      timeout-ms = <COMBO_TIMEOUT>;
      key-positions = <P_I P_N P_SHFT>;
      bindings = <&shm_in>;
    };
    combo_spm_is {
      timeout-ms = <COMBO_TIMEOUT>;
      key-positions = <P_I P_S P_SPC>;
      bindings = <&spm_is>;
    };
    combo_shm_is {
      timeout-ms = <COMBO_TIMEOUT>;
      key-positions = <P_I P_S P_SHFT>;
      bindings = <&shm_is>;
    };
    combo_lm_is {
      timeout-ms = <COMBO_TIMEOUT>;
      key-positions = <P_I P_S P_LALT>;
      bindings = <&lm_is>;
    };
    combo_lsm_is {
      timeout-ms = <COMBO_TIMEOUT>;
      key-positions = <P_I P_S P_LALT P_SHFT>;
      bindings = <&lsm_is>;
    };
    combo_spm_it {
      timeout-ms = <COMBO_TIMEOUT>;
      key-positions = <P_I P_T P_SPC>;
      bindings = <&spm_it>;
    };
    combo_shm_it {
      timeout-ms = <COMBO_TIMEOUT>;
      key-positions = <P_I P_T P_SHFT>;
      bindings = <&shm_it>;
    };
    combo_lm_it {
      timeout-ms = <COMBO_TIMEOUT>;
      key-positions = <P_I P_T P_LALT>;
      bindings = <&lm_it>;
    };
    combo_lsm_it {
      timeout-ms = <COMBO_TIMEOUT>;
      key-positions = <P_I P_T P_LALT P_SHFT>;
      bindings = <&lsm_it>;
    };
    combo_rm_it {
      timeout-ms = <COMBO_TIMEOUT>;
      key-positions = <P_I P_T P_RALT>;
      bindings = <&rm_it>;
    };
    combo_rsm_it {
      timeout-ms = <COMBO_TIMEOUT>;
      key-positions = <P_I P_T P_RALT P_SPC>;
      bindings = <&rsm_it>;
    };
    combo_spm_me {
      timeout-ms = <COMBO_TIMEOUT>;
      key-positions = <P_M P_E P_SPC>;
      bindings = <&spm_me>;
    };
    combo_shm_me {
      timeout-ms = <COMBO_TIMEOUT>;
      key-positions = <P_M P_E P_SHFT>;
      bindings = <&shm_me>;
    };
    combo_lm_me {
      timeout-ms = <COMBO_TIMEOUT>;
      key-positions = <P_M P_E P_LALT>;
      bindings = <&lm_me>;
    };
    combo_lsm_me {
      timeout-ms = <COMBO_TIMEOUT>;
      key-positions = <P_M P_E P_LALT P_SHFT>;
      bindings = <&lsm_me>;
    };
    combo_rm_me {
      timeout-ms = <COMBO_TIMEOUT>;
      key-positions = <P_M P_E P_RALT>;
      bindings = <&rm_me>;
    };
    combo_rsm_me {
      timeout-ms = <COMBO_TIMEOUT>;
      key-positions = <P_M P_E P_RALT P_SPC>;
      bindings = <&rsm_me>;
    };
    combo_spm_no {
      timeout-ms = <COMBO_TIMEOUT>;
      key-positions = <P_N P_U P_SPC>;
      bindings = <&spm_no>;
    };
    combo_shm_no {
      timeout-ms = <COMBO_TIMEOUT>;
      key-positions = <P_N P_U P_SHFT>;
      bindings = <&shm_no>;
    };
    combo_spm_of {
      timeout-ms = <COMBO_TIMEOUT>;
      key-positions = <P_O P_F P_SPC>;
      bindings = <&spm_of>;
    };
    combo_shm_of {
      timeout-ms = <COMBO_TIMEOUT>;
      key-positions = <P_O P_F P_SHFT>;
      bindings = <&shm_of>;
    };
    combo_spm_on {
      timeout-ms = <COMBO_TIMEOUT>;
      key-positions = <P_O P_N P_SPC>;
      bindings = <&spm_on>;
    };
    combo_shm_on {
      timeout-ms = <COMBO_TIMEOUT>;
      key-positions = <P_O P_N P_SHFT>;
      bindings = <&shm_on>;
    };
    combo_spm_or {
      timeout-ms = <COMBO_TIMEOUT>;
      key-positions = <P_O P_R P_SPC>;
      bindings = <&spm_or>;
    };
    combo_shm_or {
      timeout-ms = <COMBO_TIMEOUT>;
      key-positions = <P_O P_R P_SHFT>;
      bindings = <&shm_or>;
    };
    combo_spm_so {
      timeout-ms = <COMBO_TIMEOUT>;
      key-positions = <P_S P_O P_SPC>;
      bindings = <&spm_so>;
    };
    combo_shm_so {
      timeout-ms = <COMBO_TIMEOUT>;
      key-positions = <P_S P_O P_SHFT>;
      bindings = <&shm_so>;
    };
    combo_spm_to {
      timeout-ms = <COMBO_TIMEOUT>;
      key-positions = <P_T P_O P_SPC>;
      bindings = <&spm_to>;
    };
    combo_shm_to {
      timeout-ms = <COMBO_TIMEOUT>;
      key-positions = <P_T P_O P_SHFT>;
      bindings = <&shm_to>;
    };
    combo_spm_up {
      timeout-ms = <COMBO_TIMEOUT>;
      key-positions = <P_U P_P P_SPC>;
      bindings = <&spm_up>;
    };
    combo_shm_up {
      timeout-ms = <COMBO_TIMEOUT>;
      key-positions = <P_U P_P P_SHFT>;
      bindings = <&shm_up>;
    };
    combo_spm_us {
      timeout-ms = <COMBO_TIMEOUT>;
      key-positions = <P_U P_S P_SPC>;
      bindings = <&spm_us>;
    };
    combo_shm_us {
      timeout-ms = <COMBO_TIMEOUT>;
      key-positions = <P_U P_S P_SHFT>;
      bindings = <&shm_us>;
    };
    combo_spm_we {
      timeout-ms = <COMBO_TIMEOUT>;
      key-positions = <P_W P_E P_SPC>;
      bindings = <&spm_we>;
    };
    combo_shm_we {
      timeout-ms = <COMBO_TIMEOUT>;
      key-positions = <P_W P_E P_SHFT>;
      bindings = <&shm_we>;
    };
    combo_spm_weSQTre {
      timeout-ms = <COMBO_TIMEOUT>;
      key-positions = <P_W P_R P_SPC>;
      bindings = <&spm_weSQTre>;
    };
    combo_shm_weSQTre {
      timeout-ms = <COMBO_TIMEOUT>;
      key-positions = <P_W P_R P_SHFT>;
      bindings = <&shm_weSQTre>;
    };
    combo_lm_weSQTre {
      timeout-ms = <COMBO_TIMEOUT>;
      key-positions = <P_W P_R P_LALT>;
      bindings = <&lm_weSQTre>;
    };
    combo_lsm_weSQTre {
      timeout-ms = <COMBO_TIMEOUT>;
      key-positions = <P_W P_R P_LALT P_SHFT>;
      bindings = <&lsm_weSQTre>;
    };
    combo_rm_weSQTre {
      timeout-ms = <COMBO_TIMEOUT>;
      key-positions = <P_W P_R P_RALT>;
      bindings = <&rm_weSQTre>;
    };
    combo_rsm_weSQTre {
      timeout-ms = <COMBO_TIMEOUT>;
      key-positions = <P_W P_R P_RALT P_SPC>;
      bindings = <&rsm_weSQTre>;
    };
    combo_spm_weSQTve {
      timeout-ms = <COMBO_TIMEOUT>;
      key-positions = <P_W P_V P_SPC>;
      bindings = <&spm_weSQTve>;
    };
    combo_shm_weSQTve {
      timeout-ms = <COMBO_TIMEOUT>;
      key-positions = <P_W P_V P_SHFT>;
      bindings = <&shm_weSQTve>;
    };
    combo_spm_weSQTll {
      timeout-ms = <COMBO_TIMEOUT>;
      key-positions = <P_W P_L P_SPC>;
      bindings = <&spm_weSQTll>;
    };
    combo_shm_weSQTll {
      timeout-ms = <COMBO_TIMEOUT>;
      key-positions = <P_W P_L P_SHFT>;
      bindings = <&shm_weSQTll>;
    };
    combo_spm_OK {
      timeout-ms = <COMBO_TIMEOUT>;
      key-positions = <P_O P_K P_SPC>;
      bindings = <&spm_OK>;
    };
    combo_shm_OK {
      timeout-ms = <COMBO_TIMEOUT>;
      key-positions = <P_O P_K P_SHFT>;
      bindings = <&shm_OK>;
    };
    combo_spm_all {
      timeout-ms = <COMBO_TIMEOUT>;
      key-positions = <P_A P_L P_SPC>;
      bindings = <&spm_all>;
    };
    combo_shm_all {
      timeout-ms = <COMBO_TIMEOUT>;
      key-positions = <P_A P_L P_SHFT>;
      bindings = <&shm_all>;
    };
    combo_spm_and {
      timeout-ms = <COMBO_TIMEOUT>;
      key-positions = <P_A P_D P_SPC>;
      bindings = <&spm_and>;
    };
    combo_shm_and {
      timeout-ms = <COMBO_TIMEOUT>;
      key-positions = <P_A P_D P_SHFT>;
      bindings = <&shm_and>;
    };
    combo_spm_any {
      timeout-ms = <COMBO_TIMEOUT>;
      key-positions = <P_A P_Y P_SPC>;
      bindings = <&spm_any>;
    };
    combo_shm_any {
      timeout-ms = <COMBO_TIMEOUT>;
      key-positions = <P_A P_Y P_SHFT>;
      bindings = <&shm_any>;
    };
    combo_spm_but {
      timeout-ms = <COMBO_TIMEOUT>;
      key-positions = <P_B P_U P_SPC>;
      bindings = <&spm_but>;
    };
    combo_shm_but {
      timeout-ms = <COMBO_TIMEOUT>;
      key-positions = <P_B P_U P_SHFT>;
      bindings = <&shm_but>;
    };
    combo_spm_can {
      timeout-ms = <COMBO_TIMEOUT>;
      key-positions = <P_C P_N P_SPC>;
      bindings = <&spm_can>;
    };
    combo_shm_can {
      timeout-ms = <COMBO_TIMEOUT>;
      key-positions = <P_C P_N P_SHFT>;
      bindings = <&shm_can>;
    };
    combo_lm_can {
      timeout-ms = <COMBO_TIMEOUT>;
      key-positions = <P_C P_N P_LALT>;
      bindings = <&lm_can>;
    };
    combo_lsm_can {
      timeout-ms = <COMBO_TIMEOUT>;
      key-positions = <P_C P_N P_LALT P_SHFT>;
      bindings = <&lsm_can>;
    };
    combo_spm_could {
      timeout-ms = <COMBO_TIMEOUT>;
      key-positions = <P_C P_D P_SPC>;
      bindings = <&spm_could>;
    };
    combo_shm_could {
      timeout-ms = <COMBO_TIMEOUT>;
      key-positions = <P_C P_D P_SHFT>;
      bindings = <&shm_could>;
    };
    combo_lm_could {
      timeout-ms = <COMBO_TIMEOUT>;
      key-positions = <P_C P_D P_LALT>;
      bindings = <&lm_could>;
    };
    combo_lsm_could {
      timeout-ms = <COMBO_TIMEOUT>;
      key-positions = <P_C P_D P_LALT P_SHFT>;
      bindings = <&lsm_could>;
    };
    combo_spm_day {
      timeout-ms = <COMBO_TIMEOUT>;
      key-positions = <P_D P_Y P_SPC>;
      bindings = <&spm_day>;
    };
    combo_shm_day {
      timeout-ms = <COMBO_TIMEOUT>;
      key-positions = <P_D P_Y P_SHFT>;
      bindings = <&shm_day>;
    };
    combo_lm_day {
      timeout-ms = <COMBO_TIMEOUT>;
      key-positions = <P_D P_Y P_LALT>;
      bindings = <&lm_day>;
    };
    combo_lsm_day {
      timeout-ms = <COMBO_TIMEOUT>;
      key-positions = <P_D P_Y P_LALT P_SHFT>;
      bindings = <&lsm_day>;
    };
    combo_spm_for {
      timeout-ms = <COMBO_TIMEOUT>;
      key-positions = <P_F P_R P_SPC>;
      bindings = <&spm_for>;
    };
    combo_shm_for {
      timeout-ms = <COMBO_TIMEOUT>;
      key-positions = <P_F P_R P_SHFT>;
      bindings = <&shm_for>;
    };
    combo_spm_get {
      timeout-ms = <COMBO_TIMEOUT>;
      key-positions = <P_G P_E P_SPC>;
      bindings = <&spm_get>;
    };
    combo_shm_get {
      timeout-ms = <COMBO_TIMEOUT>;
      key-positions = <P_G P_E P_SHFT>;
      bindings = <&shm_get>;
    };
    combo_lm_get {
      timeout-ms = <COMBO_TIMEOUT>;
      key-positions = <P_G P_E P_LALT>;
      bindings = <&lm_get>;
    };
    combo_lsm_get {
      timeout-ms = <COMBO_TIMEOUT>;
      key-positions = <P_G P_E P_LALT P_SHFT>;
      bindings = <&lsm_get>;
    };
    combo_rm_get {
      timeout-ms = <COMBO_TIMEOUT>;
      key-positions = <P_G P_E P_RALT>;
      bindings = <&rm_get>;
    };
    combo_rsm_get {
      timeout-ms = <COMBO_TIMEOUT>;
      key-positions = <P_G P_E P_RALT P_SPC>;
      bindings = <&rsm_get>;
    };
    combo_spm_how {
      timeout-ms = <COMBO_TIMEOUT>;
      key-positions = <P_H P_O P_SPC>;
      bindings = <&spm_how>;
    };
    combo_shm_how {
      timeout-ms = <COMBO_TIMEOUT>;
      key-positions = <P_H P_O P_SHFT>;
      bindings = <&shm_how>;
    };
    combo_spm_new {
      timeout-ms = <COMBO_TIMEOUT>;
      key-positions = <P_N P_E P_SPC>;
      bindings = <&spm_new>;
    };
    combo_shm_new {
      timeout-ms = <COMBO_TIMEOUT>;
      key-positions = <P_N P_E P_SHFT>;
      bindings = <&shm_new>;
    };
    combo_spm_not {
      timeout-ms = <COMBO_TIMEOUT>;
      key-positions = <P_N P_T P_SPC>;
      bindings = <&spm_not>;
    };
    combo_shm_not {
      timeout-ms = <COMBO_TIMEOUT>;
      key-positions = <P_N P_T P_SHFT>;
      bindings = <&shm_not>;
    };
    combo_spm_now {
      timeout-ms = <COMBO_TIMEOUT>;
      key-positions = <P_N P_W P_SPC>;
      bindings = <&spm_now>;
    };
    combo_shm_now {
      timeout-ms = <COMBO_TIMEOUT>;
      key-positions = <P_N P_W P_SHFT>;
      bindings = <&shm_now>;
    };
    combo_spm_one {
      timeout-ms = <COMBO_TIMEOUT>;
      key-positions = <P_O P_E P_SPC>;
      bindings = <&spm_one>;
    };
    combo_shm_one {
      timeout-ms = <COMBO_TIMEOUT>;
      key-positions = <P_O P_E P_SHFT>;
      bindings = <&shm_one>;
    };
    combo_spm_our {
      timeout-ms = <COMBO_TIMEOUT>;
      key-positions = <P_O P_U P_SPC>;
      bindings = <&spm_our>;
    };
    combo_shm_our {
      timeout-ms = <COMBO_TIMEOUT>;
      key-positions = <P_O P_U P_SHFT>;
      bindings = <&shm_our>;
    };
    combo_lm_our {
      timeout-ms = <COMBO_TIMEOUT>;
      key-positions = <P_O P_U P_LALT>;
      bindings = <&lm_our>;
    };
    combo_lsm_our {
      timeout-ms = <COMBO_TIMEOUT>;
      key-positions = <P_O P_U P_LALT P_SHFT>;
      bindings = <&lsm_our>;
    };
    combo_spm_out {
      timeout-ms = <COMBO_TIMEOUT>;
      key-positions = <P_O P_A P_SPC>;
      bindings = <&spm_out>;
    };
    combo_shm_out {
      timeout-ms = <COMBO_TIMEOUT>;
      key-positions = <P_O P_A P_SHFT>;
      bindings = <&shm_out>;
    };
    combo_spm_say {
      timeout-ms = <COMBO_TIMEOUT>;
      key-positions = <P_S P_Y P_SPC>;
      bindings = <&spm_say>;
    };
    combo_shm_say {
      timeout-ms = <COMBO_TIMEOUT>;
      key-positions = <P_S P_Y P_SHFT>;
      bindings = <&shm_say>;
    };
    combo_lm_say {
      timeout-ms = <COMBO_TIMEOUT>;
      key-positions = <P_S P_Y P_LALT>;
      bindings = <&lm_say>;
    };
    combo_lsm_say {
      timeout-ms = <COMBO_TIMEOUT>;
      key-positions = <P_S P_Y P_LALT P_SHFT>;
      bindings = <&lsm_say>;
    };
    combo_rm_say {
      timeout-ms = <COMBO_TIMEOUT>;
      key-positions = <P_S P_Y P_RALT>;
      bindings = <&rm_say>;
    };
    combo_rsm_say {
      timeout-ms = <COMBO_TIMEOUT>;
      key-positions = <P_S P_Y P_RALT P_SPC>;
      bindings = <&rsm_say>;
    };
    combo_spm_see {
      timeout-ms = <COMBO_TIMEOUT>;
      key-positions = <P_S P_E P_SPC>;
      bindings = <&spm_see>;
    };
    combo_shm_see {
      timeout-ms = <COMBO_TIMEOUT>;
      key-positions = <P_S P_E P_SHFT>;
      bindings = <&shm_see>;
    };
    combo_lm_see {
      timeout-ms = <COMBO_TIMEOUT>;
      key-positions = <P_S P_E P_LALT>;
      bindings = <&lm_see>;
    };
    combo_lsm_see {
      timeout-ms = <COMBO_TIMEOUT>;
      key-positions = <P_S P_E P_LALT P_SHFT>;
      bindings = <&lsm_see>;
    };
    combo_rm_see {
      timeout-ms = <COMBO_TIMEOUT>;
      key-positions = <P_S P_E P_RALT>;
      bindings = <&rm_see>;
    };
    combo_rsm_see {
      timeout-ms = <COMBO_TIMEOUT>;
      key-positions = <P_S P_E P_RALT P_SPC>;
      bindings = <&rsm_see>;
    };
    combo_spm_she {
      timeout-ms = <COMBO_TIMEOUT>;
      key-positions = <P_S P_H P_SPC>;
      bindings = <&spm_she>;
    };
    combo_shm_she {
      timeout-ms = <COMBO_TIMEOUT>;
      key-positions = <P_S P_H P_SHFT>;
      bindings = <&shm_she>;
    };
    combo_lm_she {
      timeout-ms = <COMBO_TIMEOUT>;
      key-positions = <P_S P_H P_LALT>;
      bindings = <&lm_she>;
    };
    combo_lsm_she {
      timeout-ms = <COMBO_TIMEOUT>;
      key-positions = <P_S P_H P_LALT P_SHFT>;
      bindings = <&lsm_she>;
    };
    combo_rm_she {
      timeout-ms = <COMBO_TIMEOUT>;
      key-positions = <P_S P_H P_RALT>;
      bindings = <&rm_she>;
    };
    combo_rsm_she {
      timeout-ms = <COMBO_TIMEOUT>;
      key-positions = <P_S P_H P_RALT P_SPC>;
      bindings = <&rsm_she>;
    };
    combo_spm_the {
      timeout-ms = <COMBO_TIMEOUT>;
      key-positions = <P_T P_E P_SPC>;
      bindings = <&spm_the>;
    };
    combo_shm_the {
      timeout-ms = <COMBO_TIMEOUT>;
      key-positions = <P_T P_E P_SHFT>;
      bindings = <&shm_the>;
    };
    combo_spm_two {
      timeout-ms = <COMBO_TIMEOUT>;
      key-positions = <P_T P_W P_SPC>;
      bindings = <&spm_two>;
    };
    combo_shm_two {
      timeout-ms = <COMBO_TIMEOUT>;
      key-positions = <P_T P_W P_SHFT>;
      bindings = <&shm_two>;
    };
    combo_spm_use {
      timeout-ms = <COMBO_TIMEOUT>;
      key-positions = <P_U P_E P_SPC>;
      bindings = <&spm_use>;
    };
    combo_shm_use {
      timeout-ms = <COMBO_TIMEOUT>;
      key-positions = <P_U P_E P_SHFT>;
      bindings = <&shm_use>;
    };
    combo_lm_use {
      timeout-ms = <COMBO_TIMEOUT>;
      key-positions = <P_U P_E P_LALT>;
      bindings = <&lm_use>;
    };
    combo_lsm_use {
      timeout-ms = <COMBO_TIMEOUT>;
      key-positions = <P_U P_E P_LALT P_SHFT>;
      bindings = <&lsm_use>;
    };
    combo_rm_use {
      timeout-ms = <COMBO_TIMEOUT>;
      key-positions = <P_U P_E P_RALT>;
      bindings = <&rm_use>;
    };
    combo_rsm_use {
      timeout-ms = <COMBO_TIMEOUT>;
      key-positions = <P_U P_E P_RALT P_SPC>;
      bindings = <&rsm_use>;
    };
    combo_spm_was {
      timeout-ms = <COMBO_TIMEOUT>;
      key-positions = <P_W P_S P_SPC>;
      bindings = <&spm_was>;
    };
    combo_shm_was {
      timeout-ms = <COMBO_TIMEOUT>;
      key-positions = <P_W P_S P_SHFT>;
      bindings = <&shm_was>;
    };
    combo_spm_way {
      timeout-ms = <COMBO_TIMEOUT>;
      key-positions = <P_W P_A P_SPC>;
      bindings = <&spm_way>;
    };
    combo_shm_way {
      timeout-ms = <COMBO_TIMEOUT>;
      key-positions = <P_W P_A P_SHFT>;
      bindings = <&shm_way>;
    };
    combo_spm_who {
      timeout-ms = <COMBO_TIMEOUT>;
      key-positions = <P_W P_O P_SPC>;
      bindings = <&spm_who>;
    };
    combo_shm_who {
      timeout-ms = <COMBO_TIMEOUT>;
      key-positions = <P_W P_O P_SHFT>;
      bindings = <&shm_who>;
    };
    combo_spm_you {
      timeout-ms = <COMBO_TIMEOUT>;
      key-positions = <P_Y P_U P_SPC>;
      bindings = <&spm_you>;
    };
    combo_shm_you {
      timeout-ms = <COMBO_TIMEOUT>;
      key-positions = <P_Y P_U P_SHFT>;
      bindings = <&shm_you>;
    };
    combo_lm_you {
      timeout-ms = <COMBO_TIMEOUT>;
      key-positions = <P_Y P_U P_LALT>;
      bindings = <&lm_you>;
    };
    combo_lsm_you {
      timeout-ms = <COMBO_TIMEOUT>;
      key-positions = <P_Y P_U P_LALT P_SHFT>;
      bindings = <&lsm_you>;
    };
    combo_rm_you {
      timeout-ms = <COMBO_TIMEOUT>;
      key-positions = <P_Y P_U P_RALT>;
      bindings = <&rm_you>;
    };
    combo_rsm_you {
      timeout-ms = <COMBO_TIMEOUT>;
      key-positions = <P_Y P_U P_RALT P_SPC>;
      bindings = <&rsm_you>;
    };
    combo_spm_youSQTre {
      timeout-ms = <COMBO_TIMEOUT>;
      key-positions = <P_Y P_R P_SPC>;
      bindings = <&spm_youSQTre>;
    };
    combo_shm_youSQTre {
      timeout-ms = <COMBO_TIMEOUT>;
      key-positions = <P_Y P_R P_SHFT>;
      bindings = <&shm_youSQTre>;
    };
    combo_lm_youSQTre {
      timeout-ms = <COMBO_TIMEOUT>;
      key-positions = <P_Y P_R P_LALT>;
      bindings = <&lm_youSQTre>;
    };
    combo_lsm_youSQTre {
      timeout-ms = <COMBO_TIMEOUT>;
      key-positions = <P_Y P_R P_LALT P_SHFT>;
      bindings = <&lsm_youSQTre>;
    };
    combo_rm_youSQTre {
      timeout-ms = <COMBO_TIMEOUT>;
      key-positions = <P_Y P_R P_RALT>;
      bindings = <&rm_youSQTre>;
    };
    combo_rsm_youSQTre {
      timeout-ms = <COMBO_TIMEOUT>;
      key-positions = <P_Y P_R P_RALT P_SPC>;
      bindings = <&rsm_youSQTre>;
    };
    combo_spm_youSQTve {
      timeout-ms = <COMBO_TIMEOUT>;
      key-positions = <P_Y P_V P_SPC>;
      bindings = <&spm_youSQTve>;
    };
    combo_shm_youSQTve {
      timeout-ms = <COMBO_TIMEOUT>;
      key-positions = <P_Y P_V P_SHFT>;
      bindings = <&shm_youSQTve>;
    };
    combo_spm_youSQTll {
      timeout-ms = <COMBO_TIMEOUT>;
      key-positions = <P_Y P_L P_SPC>;
      bindings = <&spm_youSQTll>;
    };
    combo_shm_youSQTll {
      timeout-ms = <COMBO_TIMEOUT>;
      key-positions = <P_Y P_L P_SHFT>;
      bindings = <&shm_youSQTll>;
    };
    combo_spm_also {
      timeout-ms = <COMBO_TIMEOUT>;
      key-positions = <P_A P_C P_SPC>;
      bindings = <&spm_also>;
    };
    combo_shm_also {
      timeout-ms = <COMBO_TIMEOUT>;
      key-positions = <P_A P_C P_SHFT>;
      bindings = <&shm_also>;
    };
    combo_spm_back {
      timeout-ms = <COMBO_TIMEOUT>;
      key-positions = <P_B P_A P_SPC>;
      bindings = <&spm_back>;
    };
    combo_shm_back {
      timeout-ms = <COMBO_TIMEOUT>;
      key-positions = <P_B P_A P_SHFT>;
      bindings = <&shm_back>;
    };
    combo_spm_come {
      timeout-ms = <COMBO_TIMEOUT>;
      key-positions = <P_C P_E P_SPC>;
      bindings = <&spm_come>;
    };
    combo_shm_come {
      timeout-ms = <COMBO_TIMEOUT>;
      key-positions = <P_C P_E P_SHFT>;
      bindings = <&shm_come>;
    };
    combo_lm_come {
      timeout-ms = <COMBO_TIMEOUT>;
      key-positions = <P_C P_E P_LALT>;
      bindings = <&lm_come>;
    };
    combo_lsm_come {
      timeout-ms = <COMBO_TIMEOUT>;
      key-positions = <P_C P_E P_LALT P_SHFT>;
      bindings = <&lsm_come>;
    };
    combo_rm_come {
      timeout-ms = <COMBO_TIMEOUT>;
      key-positions = <P_C P_E P_RALT>;
      bindings = <&rm_come>;
    };
    combo_rsm_come {
      timeout-ms = <COMBO_TIMEOUT>;
      key-positions = <P_C P_E P_RALT P_SPC>;
      bindings = <&rsm_come>;
    };
    combo_spm_even {
      timeout-ms = <COMBO_TIMEOUT>;
      key-positions = <P_E P_V P_SPC>;
      bindings = <&spm_even>;
    };
    combo_shm_even {
      timeout-ms = <COMBO_TIMEOUT>;
      key-positions = <P_E P_V P_SHFT>;
      bindings = <&shm_even>;
    };
    combo_spm_from {
      timeout-ms = <COMBO_TIMEOUT>;
      key-positions = <P_F P_M P_SPC>;
      bindings = <&spm_from>;
    };
    combo_shm_from {
      timeout-ms = <COMBO_TIMEOUT>;
      key-positions = <P_F P_M P_SHFT>;
      bindings = <&shm_from>;
    };
    combo_spm_give {
      timeout-ms = <COMBO_TIMEOUT>;
      key-positions = <P_G P_I P_SPC>;
      bindings = <&spm_give>;
    };
    combo_shm_give {
      timeout-ms = <COMBO_TIMEOUT>;
      key-positions = <P_G P_I P_SHFT>;
      bindings = <&shm_give>;
    };
    combo_lm_give {
      timeout-ms = <COMBO_TIMEOUT>;
      key-positions = <P_G P_I P_LALT>;
      bindings = <&lm_give>;
    };
    combo_lsm_give {
      timeout-ms = <COMBO_TIMEOUT>;
      key-positions = <P_G P_I P_LALT P_SHFT>;
      bindings = <&lsm_give>;
    };
    combo_rm_give {
      timeout-ms = <COMBO_TIMEOUT>;
      key-positions = <P_G P_I P_RALT>;
      bindings = <&rm_give>;
    };
    combo_rsm_give {
      timeout-ms = <COMBO_TIMEOUT>;
      key-positions = <P_G P_I P_RALT P_SPC>;
      bindings = <&rsm_give>;
    };
    combo_spm_good {
      timeout-ms = <COMBO_TIMEOUT>;
      key-positions = <P_G P_D P_SPC>;
      bindings = <&spm_good>;
    };
    combo_shm_good {
      timeout-ms = <COMBO_TIMEOUT>;
      key-positions = <P_G P_D P_SHFT>;
      bindings = <&shm_good>;
    };
    combo_spm_have {
      timeout-ms = <COMBO_TIMEOUT>;
      key-positions = <P_H P_A P_SPC>;
      bindings = <&spm_have>;
    };
    combo_shm_have {
      timeout-ms = <COMBO_TIMEOUT>;
      key-positions = <P_H P_A P_SHFT>;
      bindings = <&shm_have>;
    };
    combo_lm_have {
      timeout-ms = <COMBO_TIMEOUT>;
      key-positions = <P_H P_A P_LALT>;
      bindings = <&lm_have>;
    };
    combo_lsm_have {
      timeout-ms = <COMBO_TIMEOUT>;
      key-positions = <P_H P_A P_LALT P_SHFT>;
      bindings = <&lsm_have>;
    };
    combo_rm_have {
      timeout-ms = <COMBO_TIMEOUT>;
      key-positions = <P_H P_A P_RALT>;
      bindings = <&rm_have>;
    };
    combo_rsm_have {
      timeout-ms = <COMBO_TIMEOUT>;
      key-positions = <P_H P_A P_RALT P_SPC>;
      bindings = <&rsm_have>;
    };
    combo_spm_into {
      timeout-ms = <COMBO_TIMEOUT>;
      key-positions = <P_I P_U P_SPC>;
      bindings = <&spm_into>;
    };
    combo_shm_into {
      timeout-ms = <COMBO_TIMEOUT>;
      key-positions = <P_I P_U P_SHFT>;
      bindings = <&shm_into>;
    };
    combo_spm_just {
      timeout-ms = <COMBO_TIMEOUT>;
      key-positions = <P_J P_T P_SPC>;
      bindings = <&spm_just>;
    };
    combo_shm_just {
      timeout-ms = <COMBO_TIMEOUT>;
      key-positions = <P_J P_T P_SHFT>;
      bindings = <&shm_just>;
    };
    combo_spm_know {
      timeout-ms = <COMBO_TIMEOUT>;
      key-positions = <P_K P_N P_SPC>;
      bindings = <&spm_know>;
    };
    combo_shm_know {
      timeout-ms = <COMBO_TIMEOUT>;
      key-positions = <P_K P_N P_SHFT>;
      bindings = <&shm_know>;
    };
    combo_lm_know {
      timeout-ms = <COMBO_TIMEOUT>;
      key-positions = <P_K P_N P_LALT>;
      bindings = <&lm_know>;
    };
    combo_lsm_know {
      timeout-ms = <COMBO_TIMEOUT>;
      key-positions = <P_K P_N P_LALT P_SHFT>;
      bindings = <&lsm_know>;
    };
    combo_rm_know {
      timeout-ms = <COMBO_TIMEOUT>;
      key-positions = <P_K P_N P_RALT>;
      bindings = <&rm_know>;
    };
    combo_rsm_know {
      timeout-ms = <COMBO_TIMEOUT>;
      key-positions = <P_K P_N P_RALT P_SPC>;
      bindings = <&rsm_know>;
    };
    combo_spm_like {
      timeout-ms = <COMBO_TIMEOUT>;
      key-positions = <P_L P_E P_SPC>;
      bindings = <&spm_like>;
    };
    combo_shm_like {
      timeout-ms = <COMBO_TIMEOUT>;
      key-positions = <P_L P_E P_SHFT>;
      bindings = <&shm_like>;
    };
    combo_lm_like {
      timeout-ms = <COMBO_TIMEOUT>;
      key-positions = <P_L P_E P_LALT>;
      bindings = <&lm_like>;
    };
    combo_lsm_like {
      timeout-ms = <COMBO_TIMEOUT>;
      key-positions = <P_L P_E P_LALT P_SHFT>;
      bindings = <&lsm_like>;
    };
    combo_rm_like {
      timeout-ms = <COMBO_TIMEOUT>;
      key-positions = <P_L P_E P_RALT>;
      bindings = <&rm_like>;
    };
    combo_rsm_like {
      timeout-ms = <COMBO_TIMEOUT>;
      key-positions = <P_L P_E P_RALT P_SPC>;
      bindings = <&rsm_like>;
    };
    combo_spm_look {
      timeout-ms = <COMBO_TIMEOUT>;
      key-positions = <P_L P_K P_SPC>;
      bindings = <&spm_look>;
    };
    combo_shm_look {
      timeout-ms = <COMBO_TIMEOUT>;
      key-positions = <P_L P_K P_SHFT>;
      bindings = <&shm_look>;
    };
    combo_lm_look {
      timeout-ms = <COMBO_TIMEOUT>;
      key-positions = <P_L P_K P_LALT>;
      bindings = <&lm_look>;
    };
    combo_lsm_look {
      timeout-ms = <COMBO_TIMEOUT>;
      key-positions = <P_L P_K P_LALT P_SHFT>;
      bindings = <&lsm_look>;
    };
    combo_rm_look {
      timeout-ms = <COMBO_TIMEOUT>;
      key-positions = <P_L P_K P_RALT>;
      bindings = <&rm_look>;
    };
    combo_rsm_look {
      timeout-ms = <COMBO_TIMEOUT>;
      key-positions = <P_L P_K P_RALT P_SPC>;
      bindings = <&rsm_look>;
    };
    combo_spm_make {
      timeout-ms = <COMBO_TIMEOUT>;
      key-positions = <P_M P_K P_SPC>;
      bindings = <&spm_make>;
    };
    combo_shm_make {
      timeout-ms = <COMBO_TIMEOUT>;
      key-positions = <P_M P_K P_SHFT>;
      bindings = <&shm_make>;
    };
    combo_lm_make {
      timeout-ms = <COMBO_TIMEOUT>;
      key-positions = <P_M P_K P_LALT>;
      bindings = <&lm_make>;
    };
    combo_lsm_make {
      timeout-ms = <COMBO_TIMEOUT>;
      key-positions = <P_M P_K P_LALT P_SHFT>;
      bindings = <&lsm_make>;
    };
    combo_rm_make {
      timeout-ms = <COMBO_TIMEOUT>;
      key-positions = <P_M P_K P_RALT>;
      bindings = <&rm_make>;
    };
    combo_rsm_make {
      timeout-ms = <COMBO_TIMEOUT>;
      key-positions = <P_M P_K P_RALT P_SPC>;
      bindings = <&rsm_make>;
    };
    combo_spm_most {
      timeout-ms = <COMBO_TIMEOUT>;
      key-positions = <P_M P_S P_SPC>;
      bindings = <&spm_most>;
    };
    combo_shm_most {
      timeout-ms = <COMBO_TIMEOUT>;
      key-positions = <P_M P_S P_SHFT>;
      bindings = <&shm_most>;
    };
    combo_spm_only {
      timeout-ms = <COMBO_TIMEOUT>;
      key-positions = <P_O P_L P_SPC>;
      bindings = <&spm_only>;
    };
    combo_shm_only {
      timeout-ms = <COMBO_TIMEOUT>;
      key-positions = <P_O P_L P_SHFT>;
      bindings = <&shm_only>;
    };
    combo_spm_over {
      timeout-ms = <COMBO_TIMEOUT>;
      key-positions = <P_O P_V P_SPC>;
      bindings = <&spm_over>;
    };
    combo_shm_over {
      timeout-ms = <COMBO_TIMEOUT>;
      key-positions = <P_O P_V P_SHFT>;
      bindings = <&shm_over>;
    };
    combo_spm_some {
      timeout-ms = <COMBO_TIMEOUT>;
      key-positions = <P_S P_N P_SPC>;
      bindings = <&spm_some>;
    };
    combo_shm_some {
      timeout-ms = <COMBO_TIMEOUT>;
      key-positions = <P_S P_N P_SHFT>;
      bindings = <&shm_some>;
    };
    combo_spm_take {
      timeout-ms = <COMBO_TIMEOUT>;
      key-positions = <P_T P_K P_SPC>;
      bindings = <&spm_take>;
    };
    combo_shm_take {
      timeout-ms = <COMBO_TIMEOUT>;
      key-positions = <P_T P_K P_SHFT>;
      bindings = <&shm_take>;
    };
    combo_lm_take {
      timeout-ms = <COMBO_TIMEOUT>;
      key-positions = <P_T P_K P_LALT>;
      bindings = <&lm_take>;
    };
    combo_lsm_take {
      timeout-ms = <COMBO_TIMEOUT>;
      key-positions = <P_T P_K P_LALT P_SHFT>;
      bindings = <&lsm_take>;
    };
    combo_rm_take {
      timeout-ms = <COMBO_TIMEOUT>;
      key-positions = <P_T P_K P_RALT>;
      bindings = <&rm_take>;
    };
    combo_rsm_take {
      timeout-ms = <COMBO_TIMEOUT>;
      key-positions = <P_T P_K P_RALT P_SPC>;
      bindings = <&rsm_take>;
    };
    combo_spm_than {
      timeout-ms = <COMBO_TIMEOUT>;
      key-positions = <P_T P_C P_SPC>;
      bindings = <&spm_than>;
    };
    combo_shm_than {
      timeout-ms = <COMBO_TIMEOUT>;
      key-positions = <P_T P_C P_SHFT>;
      bindings = <&shm_than>;
    };
    combo_spm_that {
      timeout-ms = <COMBO_TIMEOUT>;
      key-positions = <P_T P_H P_SPC>;
      bindings = <&spm_that>;
    };
    combo_shm_that {
      timeout-ms = <COMBO_TIMEOUT>;
      key-positions = <P_T P_H P_SHFT>;
      bindings = <&shm_that>;
    };
    combo_lm_that {
      timeout-ms = <COMBO_TIMEOUT>;
      key-positions = <P_T P_H P_LALT>;
      bindings = <&lm_that>;
    };
    combo_lsm_that {
      timeout-ms = <COMBO_TIMEOUT>;
      key-positions = <P_T P_H P_LALT P_SHFT>;
      bindings = <&lsm_that>;
    };
    combo_spm_them {
      timeout-ms = <COMBO_TIMEOUT>;
      key-positions = <P_T P_M P_SPC>;
      bindings = <&spm_them>;
    };
    combo_shm_them {
      timeout-ms = <COMBO_TIMEOUT>;
      key-positions = <P_T P_M P_SHFT>;
      bindings = <&shm_them>;
    };
    combo_spm_then {
      timeout-ms = <COMBO_TIMEOUT>;
      key-positions = <P_T P_U P_SPC>;
      bindings = <&spm_then>;
    };
    combo_shm_then {
      timeout-ms = <COMBO_TIMEOUT>;
      key-positions = <P_T P_U P_SHFT>;
      bindings = <&shm_then>;
    };
    combo_spm_they {
      timeout-ms = <COMBO_TIMEOUT>;
      key-positions = <P_T P_Y P_SPC>;
      bindings = <&spm_they>;
    };
    combo_shm_they {
      timeout-ms = <COMBO_TIMEOUT>;
      key-positions = <P_T P_Y P_SHFT>;
      bindings = <&shm_they>;
    };
    combo_lm_they {
      timeout-ms = <COMBO_TIMEOUT>;
      key-positions = <P_T P_Y P_LALT>;
      bindings = <&lm_they>;
    };
    combo_lsm_they {
      timeout-ms = <COMBO_TIMEOUT>;
      key-positions = <P_T P_Y P_LALT P_SHFT>;
      bindings = <&lsm_they>;
    };
    combo_rm_they {
      timeout-ms = <COMBO_TIMEOUT>;
      key-positions = <P_T P_Y P_RALT>;
      bindings = <&rm_they>;
    };
    combo_rsm_they {
      timeout-ms = <COMBO_TIMEOUT>;
      key-positions = <P_T P_Y P_RALT P_SPC>;
      bindings = <&rsm_they>;
    };
    combo_spm_theySQTre {
      timeout-ms = <COMBO_TIMEOUT>;
      key-positions = <P_T P_R P_SPC>;
      bindings = <&spm_theySQTre>;
    };
    combo_shm_theySQTre {
      timeout-ms = <COMBO_TIMEOUT>;
      key-positions = <P_T P_R P_SHFT>;
      bindings = <&shm_theySQTre>;
    };
    combo_spm_theySQTve {
      timeout-ms = <COMBO_TIMEOUT>;
      key-positions = <P_T P_V P_SPC>;
      bindings = <&spm_theySQTve>;
    };
    combo_shm_theySQTve {
      timeout-ms = <COMBO_TIMEOUT>;
      key-positions = <P_T P_V P_SHFT>;
      bindings = <&shm_theySQTve>;
    };
    combo_spm_theySQTll {
      timeout-ms = <COMBO_TIMEOUT>;
      key-positions = <P_T P_L P_SPC>;
      bindings = <&spm_theySQTll>;
    };
    combo_shm_theySQTll {
      timeout-ms = <COMBO_TIMEOUT>;
      key-positions = <P_T P_L P_SHFT>;
      bindings = <&shm_theySQTll>;
    };
    combo_spm_this {
      timeout-ms = <COMBO_TIMEOUT>;
      key-positions = <P_T P_S P_SPC>;
      bindings = <&spm_this>;
    };
    combo_shm_this {
      timeout-ms = <COMBO_TIMEOUT>;
      key-positions = <P_T P_S P_SHFT>;
      bindings = <&shm_this>;
    };
    combo_lm_this {
      timeout-ms = <COMBO_TIMEOUT>;
      key-positions = <P_T P_S P_LALT>;
      bindings = <&lm_this>;
    };
    combo_lsm_this {
      timeout-ms = <COMBO_TIMEOUT>;
      key-positions = <P_T P_S P_LALT P_SHFT>;
      bindings = <&lsm_this>;
    };
    combo_spm_time {
      timeout-ms = <COMBO_TIMEOUT>;
      key-positions = <P_T P_F P_SPC>;
      bindings = <&spm_time>;
    };
    combo_shm_time {
      timeout-ms = <COMBO_TIMEOUT>;
      key-positions = <P_T P_F P_SHFT>;
      bindings = <&shm_time>;
    };
    combo_lm_time {
      timeout-ms = <COMBO_TIMEOUT>;
      key-positions = <P_T P_F P_LALT>;
      bindings = <&lm_time>;
    };
    combo_lsm_time {
      timeout-ms = <COMBO_TIMEOUT>;
      key-positions = <P_T P_F P_LALT P_SHFT>;
      bindings = <&lsm_time>;
    };
    combo_spm_want {
      timeout-ms = <COMBO_TIMEOUT>;
      key-positions = <P_W P_F P_SPC>;
      bindings = <&spm_want>;
    };
    combo_shm_want {
      timeout-ms = <COMBO_TIMEOUT>;
      key-positions = <P_W P_F P_SHFT>;
      bindings = <&shm_want>;
    };
    combo_lm_want {
      timeout-ms = <COMBO_TIMEOUT>;
      key-positions = <P_W P_F P_LALT>;
      bindings = <&lm_want>;
    };
    combo_lsm_want {
      timeout-ms = <COMBO_TIMEOUT>;
      key-positions = <P_W P_F P_LALT P_SHFT>;
      bindings = <&lsm_want>;
    };
    combo_rm_want {
      timeout-ms = <COMBO_TIMEOUT>;
      key-positions = <P_W P_F P_RALT>;
      bindings = <&rm_want>;
    };
    combo_rsm_want {
      timeout-ms = <COMBO_TIMEOUT>;
      key-positions = <P_W P_F P_RALT P_SPC>;
      bindings = <&rsm_want>;
    };
    combo_spm_well {
      timeout-ms = <COMBO_TIMEOUT>;
      key-positions = <P_W P_G P_SPC>;
      bindings = <&spm_well>;
    };
    combo_shm_well {
      timeout-ms = <COMBO_TIMEOUT>;
      key-positions = <P_W P_G P_SHFT>;
      bindings = <&shm_well>;
    };
    combo_spm_what {
      timeout-ms = <COMBO_TIMEOUT>;
      key-positions = <P_W P_H P_SPC>;
      bindings = <&spm_what>;
    };
    combo_shm_what {
      timeout-ms = <COMBO_TIMEOUT>;
      key-positions = <P_W P_H P_SHFT>;
      bindings = <&shm_what>;
    };
    combo_spm_when {
      timeout-ms = <COMBO_TIMEOUT>;
      key-positions = <P_W P_U P_SPC>;
      bindings = <&spm_when>;
    };
    combo_shm_when {
      timeout-ms = <COMBO_TIMEOUT>;
      key-positions = <P_W P_U P_SHFT>;
      bindings = <&shm_when>;
    };
    combo_spm_will {
      timeout-ms = <COMBO_TIMEOUT>;
      key-positions = <P_W P_I P_SPC>;
      bindings = <&spm_will>;
    };
    combo_shm_will {
      timeout-ms = <COMBO_TIMEOUT>;
      key-positions = <P_W P_I P_SHFT>;
      bindings = <&shm_will>;
    };
    combo_lm_will {
      timeout-ms = <COMBO_TIMEOUT>;
      key-positions = <P_W P_I P_LALT>;
      bindings = <&lm_will>;
    };
    combo_lsm_will {
      timeout-ms = <COMBO_TIMEOUT>;
      key-positions = <P_W P_I P_LALT P_SHFT>;
      bindings = <&lsm_will>;
    };
    combo_spm_would {
      timeout-ms = <COMBO_TIMEOUT>;
      key-positions = <P_W P_D P_SPC>;
      bindings = <&spm_would>;
    };
    combo_shm_would {
      timeout-ms = <COMBO_TIMEOUT>;
      key-positions = <P_W P_D P_SHFT>;
      bindings = <&shm_would>;
    };
    combo_lm_would {
      timeout-ms = <COMBO_TIMEOUT>;
      key-positions = <P_W P_D P_LALT>;
      bindings = <&lm_would>;
    };
    combo_lsm_would {
      timeout-ms = <COMBO_TIMEOUT>;
      key-positions = <P_W P_D P_LALT P_SHFT>;
      bindings = <&lsm_would>;
    };
    combo_spm_with {
      timeout-ms = <COMBO_TIMEOUT>;
      key-positions = <P_W P_P P_SPC>;
      bindings = <&spm_with>;
    };
    combo_shm_with {
      timeout-ms = <COMBO_TIMEOUT>;
      key-positions = <P_W P_P P_SHFT>;
      bindings = <&shm_with>;
    };
    combo_spm_work {
      timeout-ms = <COMBO_TIMEOUT>;
      key-positions = <P_W P_K P_SPC>;
      bindings = <&spm_work>;
    };
    combo_shm_work {
      timeout-ms = <COMBO_TIMEOUT>;
      key-positions = <P_W P_K P_SHFT>;
      bindings = <&shm_work>;
    };
    combo_lm_work {
      timeout-ms = <COMBO_TIMEOUT>;
      key-positions = <P_W P_K P_LALT>;
      bindings = <&lm_work>;
    };
    combo_lsm_work {
      timeout-ms = <COMBO_TIMEOUT>;
      key-positions = <P_W P_K P_LALT P_SHFT>;
      bindings = <&lsm_work>;
    };
    combo_rm_work {
      timeout-ms = <COMBO_TIMEOUT>;
      key-positions = <P_W P_K P_RALT>;
      bindings = <&rm_work>;
    };
    combo_rsm_work {
      timeout-ms = <COMBO_TIMEOUT>;
      key-positions = <P_W P_K P_RALT P_SPC>;
      bindings = <&rsm_work>;
    };
    combo_spm_year {
      timeout-ms = <COMBO_TIMEOUT>;
      key-positions = <P_Y P_E P_SPC>;
      bindings = <&spm_year>;
    };
    combo_shm_year {
      timeout-ms = <COMBO_TIMEOUT>;
      key-positions = <P_Y P_E P_SHFT>;
      bindings = <&shm_year>;
    };
    combo_lm_year {
      timeout-ms = <COMBO_TIMEOUT>;
      key-positions = <P_Y P_E P_LALT>;
      bindings = <&lm_year>;
    };
    combo_lsm_year {
      timeout-ms = <COMBO_TIMEOUT>;
      key-positions = <P_Y P_E P_LALT P_SHFT>;
      bindings = <&lsm_year>;
    };
    combo_spm_about {
      timeout-ms = <COMBO_TIMEOUT>;
      key-positions = <P_A P_U P_SPC>;
      bindings = <&spm_about>;
    };
    combo_shm_about {
      timeout-ms = <COMBO_TIMEOUT>;
      key-positions = <P_A P_U P_SHFT>;
      bindings = <&shm_about>;
    };
    combo_spm_after {
      timeout-ms = <COMBO_TIMEOUT>;
      key-positions = <P_A P_E P_SPC>;
      bindings = <&spm_after>;
    };
    combo_shm_after {
      timeout-ms = <COMBO_TIMEOUT>;
      key-positions = <P_A P_E P_SHFT>;
      bindings = <&shm_after>;
    };
    combo_spm_first {
      timeout-ms = <COMBO_TIMEOUT>;
      key-positions = <P_F P_S P_SPC>;
      bindings = <&spm_first>;
    };
    combo_shm_first {
      timeout-ms = <COMBO_TIMEOUT>;
      key-positions = <P_F P_S P_SHFT>;
      bindings = <&shm_first>;
    };
    combo_spm_other {
      timeout-ms = <COMBO_TIMEOUT>;
      key-positions = <P_O P_P P_SPC>;
      bindings = <&spm_other>;
    };
    combo_shm_other {
      timeout-ms = <COMBO_TIMEOUT>;
      key-positions = <P_O P_P P_SHFT>;
      bindings = <&shm_other>;
    };
    combo_spm_there {
      timeout-ms = <COMBO_TIMEOUT>;
      key-positions = <P_T P_X P_SPC>;
      bindings = <&spm_there>;
    };
    combo_shm_there {
      timeout-ms = <COMBO_TIMEOUT>;
      key-positions = <P_T P_X P_SHFT>;
      bindings = <&shm_there>;
    };
    combo_spm_think {
      timeout-ms = <COMBO_TIMEOUT>;
      key-positions = <P_T P_Q P_SPC>;
      bindings = <&spm_think>;
    };
    combo_shm_think {
      timeout-ms = <COMBO_TIMEOUT>;
      key-positions = <P_T P_Q P_SHFT>;
      bindings = <&shm_think>;
    };
    combo_lm_think {
      timeout-ms = <COMBO_TIMEOUT>;
      key-positions = <P_T P_Q P_LALT>;
      bindings = <&lm_think>;
    };
    combo_lsm_think {
      timeout-ms = <COMBO_TIMEOUT>;
      key-positions = <P_T P_Q P_LALT P_SHFT>;
      bindings = <&lsm_think>;
    };
    combo_rm_think {
      timeout-ms = <COMBO_TIMEOUT>;
      key-positions = <P_T P_Q P_RALT>;
      bindings = <&rm_think>;
    };
    combo_rsm_think {
      timeout-ms = <COMBO_TIMEOUT>;
      key-positions = <P_T P_Q P_RALT P_SPC>;
      bindings = <&rsm_think>;
    };
    combo_spm_which {
      timeout-ms = <COMBO_TIMEOUT>;
      key-positions = <P_W P_C P_SPC>;
      bindings = <&spm_which>;
    };
    combo_shm_which {
      timeout-ms = <COMBO_TIMEOUT>;
      key-positions = <P_W P_C P_SHFT>;
      bindings = <&shm_which>;
    };
    combo_spm_people {
      timeout-ms = <COMBO_TIMEOUT>;
      key-positions = <P_P P_E P_SPC>;
      bindings = <&spm_people>;
    };
    combo_shm_people {
      timeout-ms = <COMBO_TIMEOUT>;
      key-positions = <P_P P_E P_SHFT>;
      bindings = <&shm_people>;
    };
    combo_spm_because {
      timeout-ms = <COMBO_TIMEOUT>;
      key-positions = <P_B P_S P_SPC>;
      bindings = <&spm_because>;
    };
    combo_shm_because {
      timeout-ms = <COMBO_TIMEOUT>;
      key-positions = <P_B P_S P_SHFT>;
      bindings = <&shm_because>;
    };

    // COMBOS END
  };

  keymap {
    compatible = "zmk,keymap";

    default_layer {
      bindings = <
        DEF_Q    DEF_W    DEF_F    DEF_P    DEF_B          DEF_J    DEF_L    DEF_U    DEF_Y    DEF_SEMI
        DEF_A    DEF_R    DEF_S    DEF_T    DEF_G          DEF_M    DEF_N    DEF_E    DEF_I    DEF_O
        DEF_Z    DEF_X    DEF_C    DEF_D    DEF_V          DEF_K    DEF_H    DEF_COMA DEF_DOT  DEF_QUOT
                                   DEF_NUM  DEF_SPC        DEF_SHFT DEF_NAV
      >;
    };

    navigation_layer {
      bindings = <
        NAV_DEL  NAV_ESC  NAV_BSPC NAV_RET  MED_PRNT       GEN_TRAN NUM_LBRC NUM_RBRC NAV_TILD NAV_PIPE
        NAV_LEFT NAV_UP   NAV_DOWN NAV_RGHT NAV_TAB        GEN_TRAN GEN_CTRL GEN_GUI  GEN_ALT  GEN_MED
        NAV_HOME NAV_PGUP NAV_PGDN NAV_END  NUM_STAB       GEN_TRAN NUM_LBKT NUM_RBKT NAV_GRV  NAV_BSLH
                                   GEN_TRAN DEF_SHFT       DEF_SHFT GEN_TRAN
      >;
    };

    number_layer {
      bindings = <
        NAV_DEL  NAV_ESC  NAV_BSPC NAV_RET  MED_PRNT       NUM_PLUS NUM_N7    NUM_N8    NUM_N9    NUM_AST
        GEN_FN   GEN_ALT  GEN_GUI  GEN_CTRL NAV_TAB        NUM_EQUL NUM_N4    NUM_N5    NUM_N6    NUM_N0
        MED_UNDO MED_CUT  MED_COPY NUM_PST  NUM_STAB       NUM_MIN  NUM_N1    NUM_N2    NUM_N3    NUM_FSLH
                                   GEN_TRAN DEF_SHFT       DEF_SHFT GEN_TRAN
      >;
    };

    media_layer {
      bindings = <
        MED_STOP MED_VOLD MED_MUTE MED_VOLU MED_BRIU       GEN_TRAN GEN_TRAN GEN_TRAN GEN_TRAN GEN_TRAN
        MED_PRNT MED_PREV MED_PLAY MED_NEXT MED_BRID       GEN_TRAN GEN_CTRL GEN_GUI  GEN_ALT  GEN_MED
        GEN_TRAN GEN_TRAN GEN_TRAN GEN_TRAN GEN_TRAN       GEN_TRAN GEN_TRAN GEN_TRAN GEN_TRAN GEN_TRAN
                                   GEN_TRAN DEF_SHFT       DEF_SHFT GEN_TRAN
      >;
    };

    function_layer {
      bindings = <
        GEN_TRAN GEN_TRAN GEN_TRAN GEN_TRAN GEN_TRAN       GEN_TRAN FUN_F7   FUN_F8   FUN_F9   FUN_F10
        GEN_FN   GEN_ALT  GEN_MED  GEN_CTRL GEN_TRAN       FUN_GAME FUN_F4   FUN_F5   FUN_F6   FUN_F11
        GEN_TRAN GEN_TRAN GEN_TRAN GEN_TRAN GEN_TRAN       GEN_TRAN FUN_F1   FUN_F2   FUN_F3   FUN_F13
                                   GEN_TRAN DEF_SHFT       DEF_SHFT GEN_TRAN
      >;
    };

    gaming_layer {
      bindings = <
        GAM_TAB  GAM_Q    GAM_W    GAM_E    GAM_R          GEN_NONE GEN_NONE GAM_UP   GEN_NONE GEN_NONE
        GAM_LSFT GAM_A    GAM_S    GAM_D    GAM_F          GAM_DEF  GAM_LEFT GAM_DOWN GAM_RGHT GEN_NONE
        GAM_LCTL GAM_Z    GAM_X    GAM_C    GAM_V          GEN_NONE GEN_NONE GEN_NONE GEN_NONE GEN_NONE
                                   GEN_TRAN GAM_SPC        GEN_TRAN GEN_TRAN
      >;
    };

    system_layer {
      bindings = <
        GEN_TRAN SYS_BTPR SYS_BTCL SYS_BTNX SYS_BLE        GEN_TRAN GEN_TRAN GEN_TRAN GEN_TRAN GEN_TRAN
        SYS_BOOT SYS_BT3  SYS_BT4  GEN_TRAN SYS_OTG        GEN_TRAN GEN_TRAN GEN_TRAN GEN_TRAN GEN_TRAN
        GEN_TRAN SYS_BT0  SYS_BT1  SYS_BT2  SYS_USB        GEN_TRAN GEN_TRAN GEN_TRAN GEN_TRAN GEN_TRAN
                                   GEN_TRAN GEN_TRAN       GEN_TRAN GEN_TRAN
      >;
    };

    // empty_layer {
    //   bindings = <
    //     GEN_TRAN GEN_TRAN GEN_TRAN GEN_TRAN GEN_TRAN       GEN_TRAN GEN_TRAN GEN_TRAN GEN_TRAN GEN_TRAN
    //     GEN_TRAN GEN_TRAN GEN_TRAN GEN_TRAN GEN_TRAN       GEN_TRAN GEN_TRAN GEN_TRAN GEN_TRAN GEN_TRAN
    //     GEN_TRAN GEN_TRAN GEN_TRAN GEN_TRAN GEN_TRAN       GEN_TRAN GEN_TRAN GEN_TRAN GEN_TRAN GEN_TRAN
    //                                GEN_TRAN GEN_TRAN       GEN_TRAN GEN_TRAN
    //   >;
    // };

  };
};
